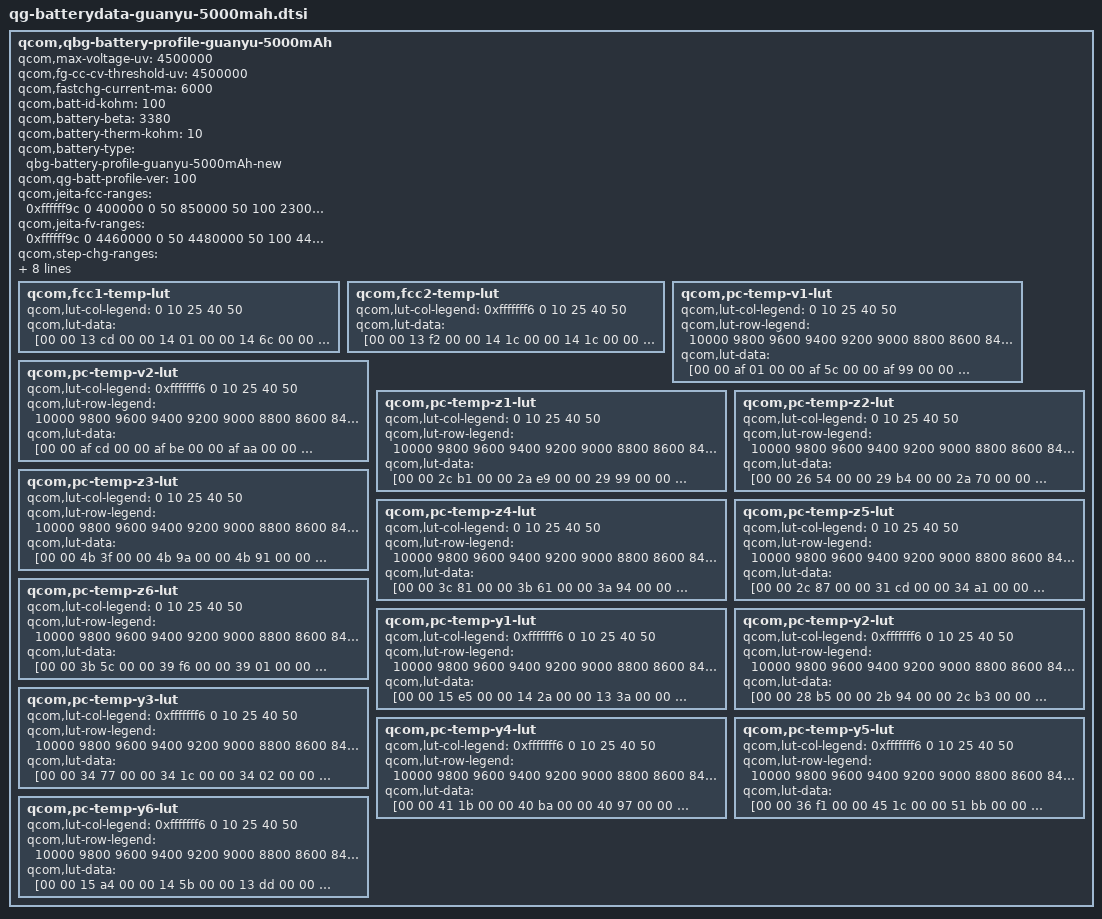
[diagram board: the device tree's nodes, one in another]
// SPDX-License-Identifier: GPL-2.0-only
/* QG battery profile qcom,qbg-battery-profile-guanyu-5000mAh (sapphire, reconstructed from stock dtbo) */

qcom,qbg-battery-profile-guanyu-5000mAh {
	qcom,max-voltage-uv = <4500000>;
	qcom,fg-cc-cv-threshold-uv = <4500000>;
	qcom,fastchg-current-ma = <6000>;
	qcom,batt-id-kohm = <100>;
	qcom,battery-beta = <3380>;
	qcom,battery-therm-kohm = <10>;
	qcom,battery-type = "qbg-battery-profile-guanyu-5000mAh-new";
	qcom,qg-batt-profile-ver = <100>;
	qcom,jeita-fcc-ranges = <0xffffff9c 0 400000 0 50 850000 50 100
	                         2300000 100 150 3700000 150 350 6000000 350
	                         480 6000000 480 560 2300000 560 1500 0>;
	qcom,jeita-fv-ranges = <0xffffff9c 0 4460000 0 50 4480000 50 100
	                        4480000 100 150 4480000 150 350 4450000 350
	                        480 4450000 480 560 4100000 560 1500 4100000>;
	qcom,step-chg-ranges = <3600000 4250000 6000000 4250001 4480000 5400000 4480001 4500000
	                        3920000>;
	qcom,vbat-avg-based-step-chg;
	qcom,taper-fcc;
	qcom,jeita-soft-thresholds = <9556 3725>;
	qcom,jeita-hard-thresholds = <17365 2971>;
	qcom,jeita-soft-hys-thresholds = <8799 4060>;
	qcom,jeita-soft-fcc-ua = <5400000 2500000>;
	qcom,jeita-soft-fv-uv = <4480000 4100000>;

	qcom,fcc1-temp-lut {
		qcom,lut-col-legend = <0 10 25 40 50>;
		qcom,lut-data = [00 00 13 cd 00 00 14 01 00 00 14 6c 00 00 14 91 00 00 14 9a];
	};

	qcom,fcc2-temp-lut {
		qcom,lut-col-legend = <0xfffffff6 0 10 25 40 50>;
		qcom,lut-data = [00 00 13 f2 00 00 14 1c 00 00 14 1c 00 00 14 80 00 00 14 7c 00 00 14 73];
	};

	qcom,pc-temp-v1-lut {
		qcom,lut-col-legend = <0 10 25 40 50>;
		qcom,lut-row-legend = <10000 9800 9600 9400 9200 9000 8800 8600
		                       8400 8200 8000 7800 7600 7400 7200 7000
		                       6800 6600 6400 6200 6000 5800 5600 5400
		                       5200 5000 4800 4600 4400 4200 4000 3800
		                       3600 3400 3200 3000 2800 2600 2400 2200
		                       2000 1800 1600 1400 1200 1000 900 800
		                       700 600 500 400 300 200 100 0>;
		qcom,lut-data = [00 00 af 01 00 00 af 5c 00 00 af 99 00 00 af b8 00 00 af c0 00 00 ad b1 00 00 ad ce 00 00 ad ed 00 00 ae 01 00 00 ae 12 00 00 ac b4 00 00 ac c2 00 00 ac c4 00 00 ac bb 00 00 ac c3 00 00 ab cb 00 00 ab ea 00 00 ab d5 00 00 ab c2 00 00 ab c3 00 00 aa e4 00 00 ab 0c 00 00 aa fb 00 00 aa e5 00 00 aa e4 00 00 aa 03 00 00 aa 28 00 00 aa 19 00 00 aa 05 00 00 aa 06 00 00 a9 15 00 00 a9 40 00 00 a9 30 00 00 a9 19 00 00 a9 1c 00 00 a8 19 00 00 a8 4b 00 00 a8 40 00 00 a8 28 00 00 a8 2c 00 00 a7 19 00 00 a7 4e 00 00 a7 44 00 00 a7 2e 00 00 a7 35 00 00 a6 1a 00 00 a6 50 00 00 a6 41 00 00 a6 2e 00 00 a6 38 00 00 a5 1a 00 00 a5 50 00 00 a5 3e 00 00 a5 2e 00 00 a5 3a 00 00 a4 1f 00 00 a4 51 00 00 a4 39 00 00 a4 2e 00 00 a4 38 00 00 a3 27 00 00 a3 56 00 00 a3 3b 00 00 a3 31 00 00 a3 38 00 00 a2 35 00 00 a2 5e 00 00 a2 43 00 00 a2 37 00 00 a2 41 00 00 a1 4c 00 00 a1 71 00 00 a1 52 00 00 a1 43 00 00 a1 51 00 00 a0 6a 00 00 a0 8c 00 00 a0 67 00 00 a0 58 00 00 a0 66 00 00 9f 90 00 00 9f ae 00 00 9f 83 00 00 9f 75 00 00 9f 7f 00 00 9e bd 00 00 9e d9 00 00 9e ab 00 00 9e 9c 00 00 9e a2 00 00 9d f4 00 00 9e 0d 00 00 9d df 00 00 9d cc 00 00 9d d0 00 00 9d 38 00 00 9d 4d 00 00 9d 1a 00 00 9d 03 00 00 9d 05 00 00 9c 82 00 00 9c 96 00 00 9c 68 00 00 9c 4c 00 00 9c 4b 00 00 9b ca 00 00 9b d8 00 00 9b b3 00 00 9b 9b 00 00 9b 9a 00 00 9b 15 00 00 9b 15 00 00 9a c4 00 00 9a bf 00 00 9a ca 00 00 9a 4b 00 00 9a 45 00 00 99 9f 00 00 99 a2 00 00 99 c4 00 00 99 3f 00 00 99 43 00 00 98 ba 00 00 98 b7 00 00 98 dd 00 00 98 3a 00 00 98 2d 00 00 98 10 00 00 98 1f 00 00 98 3c 00 00 97 9b 00 00 97 88 00 00 97 88 00 00 97 a3 00 00 97 b4 00 00 97 2a 00 00 97 2c 00 00 97 22 00 00 97 30 00 00 97 34 00 00 96 d1 00 00 96 dd 00 00 96 cd 00 00 96 ca 00 00 96 bf 00 00 96 8a 00 00 96 8b 00 00 96 7b 00 00 96 67 00 00 96 54 00 00 96 4d 00 00 96 3d 00 00 96 2b 00 00 96 07 00 00 95 f5 00 00 96 10 00 00 95 f0 00 00 95 df 00 00 95 af 00 00 95 9e 00 00 95 d7 00 00 95 a3 00 00 95 94 00 00 95 64 00 00 95 50 00 00 95 9f 00 00 95 60 00 00 95 4f 00 00 95 20 00 00 95 08 00 00 95 69 00 00 95 28 00 00 95 14 00 00 94 e0 00 00 94 c5 00 00 95 38 00 00 94 f7 00 00 94 e1 00 00 94 a4 00 00 94 8a 00 00 95 0f 00 00 94 ce 00 00 94 b2 00 00 94 69 00 00 94 48 00 00 94 ec 00 00 94 ab 00 00 94 89 00 00 94 35 00 00 93 fe 00 00 94 bd 00 00 94 7e 00 00 94 58 00 00 93 f8 00 00 93 ac 00 00 94 7c 00 00 94 38 00 00 94 05 00 00 93 a1 00 00 93 54 00 00 94 2a 00 00 93 e0 00 00 93 96 00 00 93 32 00 00 92 f3 00 00 93 bb 00 00 93 78 00 00 93 1f 00 00 92 b9 00 00 92 82 00 00 93 2d 00 00 92 f8 00 00 92 9a 00 00 92 32 00 00 91 f9 00 00 92 8c 00 00 92 58 00 00 91 f8 00 00 91 95 00 00 91 5a 00 00 91 df 00 00 91 a5 00 00 91 55 00 00 90 f9 00 00 90 be 00 00 91 38 00 00 91 02 00 00 90 e8 00 00 90 99 00 00 90 65 00 00 90 fe 00 00 90 c6 00 00 90 cc 00 00 90 83 00 00 90 4e 00 00 90 bf 00 00 90 a2 00 00 90 b6 00 00 90 73 00 00 90 3f 00 00 90 7f 00 00 90 73 00 00 90 a0 00 00 90 59 00 00 90 27 00 00 90 24 00 00 90 39 00 00 90 65 00 00 8f f6 00 00 8f b8 00 00 8e f4 00 00 8f a5 00 00 8f 6c 00 00 8e bd 00 00 8e 73 00 00 7f a0 00 00 8e 09 00 00 8d a3 00 00 8c da 00 00 8c 8c 00 00 7c 55 00 00 7e 1a 00 00 8b 33 00 00 8a 65 00 00 8a 12 00 00 79 f7 00 00 79 7d 00 00 87 ba 00 00 86 f9 00 00 86 9e 00 00 77 54 00 00 76 98 00 00 81 ea 00 00 81 67 00 00 81 0d 00 00 75 30 00 00 75 30 00 00 75 30 00 00 75 30 00 00 75 30];
	};

	qcom,pc-temp-v2-lut {
		qcom,lut-col-legend = <0xfffffff6 0 10 25 40 50>;
		qcom,lut-row-legend = <10000 9800 9600 9400 9200 9000 8800 8600
		                       8400 8200 8000 7800 7600 7400 7200 7000
		                       6800 6600 6400 6200 6000 5800 5600 5400
		                       5200 5000 4800 4600 4400 4200 4000 3800
		                       3600 3400 3200 3000 2800 2600 2400 2200
		                       2000 1800 1600 1400 1200 1000 900 800
		                       700 600 500 400 300 200 100 0>;
		qcom,lut-data = [00 00 af cd 00 00 af be 00 00 af aa 00 00 af 6e 00 00 af 5a 00 00 af 46 00 00 ad d1 00 00 ad ee 00 00 ad ee 00 00 ad da 00 00 ad b6 00 00 ad a2 00 00 ac 2e 00 00 ac 6f 00 00 ac 7f 00 00 ac 83 00 00 ac 51 00 00 ac 3b 00 00 aa ff 00 00 ab 59 00 00 ab 72 00 00 ab 78 00 00 ab 3c 00 00 ab 23 00 00 aa 20 00 00 aa 8e 00 00 aa a9 00 00 aa a3 00 00 aa 5d 00 00 aa 42 00 00 a9 49 00 00 a9 c4 00 00 a9 dd 00 00 a9 c6 00 00 a9 7b 00 00 a9 5f 00 00 a8 5f 00 00 a8 e0 00 00 a8 f9 00 00 a8 d8 00 00 a8 8d 00 00 a8 71 00 00 a7 73 00 00 a7 f4 00 00 a8 0d 00 00 a7 e5 00 00 a7 9b 00 00 a7 7f 00 00 a6 81 00 00 a7 02 00 00 a7 19 00 00 a6 ea 00 00 a6 a1 00 00 a6 85 00 00 a5 87 00 00 a6 08 00 00 a6 1b 00 00 a5 e9 00 00 a5 a1 00 00 a5 86 00 00 a4 8e 00 00 a5 0f 00 00 a5 1d 00 00 a4 e9 00 00 a4 a2 00 00 a4 87 00 00 a3 95 00 00 a4 16 00 00 a4 20 00 00 a3 e6 00 00 a3 a3 00 00 a3 89 00 00 a2 9f 00 00 a3 1e 00 00 a3 26 00 00 a2 e8 00 00 a2 a7 00 00 a2 8f 00 00 a1 ba 00 00 a2 2c 00 00 a2 31 00 00 a1 ee 00 00 a1 b0 00 00 a1 9c 00 00 a0 e2 00 00 a1 3e 00 00 a1 42 00 00 a0 f9 00 00 a0 bf 00 00 a0 ae 00 00 a0 05 00 00 a0 5a 00 00 a0 59 00 00 a0 0d 00 00 9f d7 00 00 9f c6 00 00 9f 20 00 00 9f 86 00 00 9f 74 00 00 9f 28 00 00 9e f5 00 00 9e e5 00 00 9e 31 00 00 9e b7 00 00 9e 98 00 00 9e 4d 00 00 9e 1d 00 00 9e 0d 00 00 9d 2e 00 00 9d e5 00 00 9d cc 00 00 9d 7d 00 00 9d 4f 00 00 9d 3e 00 00 9c 18 00 00 9d 10 00 00 9d 03 00 00 9c ad 00 00 9c 86 00 00 9c 77 00 00 9b 12 00 00 9c 26 00 00 9c 1d 00 00 9b de 00 00 9b c9 00 00 9b bf 00 00 9a 21 00 00 9b 0b 00 00 9b 15 00 00 9b 0c 00 00 9b 0b 00 00 9b 0b 00 00 99 3f 00 00 99 f2 00 00 9a 19 00 00 9a 1f 00 00 9a 27 00 00 9a 2e 00 00 98 65 00 00 99 14 00 00 99 2e 00 00 99 14 00 00 99 14 00 00 99 1b 00 00 97 96 00 00 98 52 00 00 98 59 00 00 98 36 00 00 98 35 00 00 98 37 00 00 96 e6 00 00 97 a8 00 00 97 ac 00 00 97 8f 00 00 97 94 00 00 97 97 00 00 96 50 00 00 97 12 00 00 97 1c 00 00 97 02 00 00 97 0d 00 00 97 10 00 00 95 d1 00 00 96 89 00 00 96 99 00 00 96 84 00 00 96 93 00 00 96 97 00 00 95 6d 00 00 96 0a 00 00 96 21 00 00 96 16 00 00 96 25 00 00 96 2a 00 00 95 19 00 00 95 96 00 00 95 b3 00 00 95 af 00 00 95 c0 00 00 95 c5 00 00 94 ce 00 00 95 2b 00 00 95 4e 00 00 95 4e 00 00 95 65 00 00 95 67 00 00 94 8a 00 00 94 c5 00 00 94 f0 00 00 94 f6 00 00 95 12 00 00 95 11 00 00 94 4b 00 00 94 6d 00 00 94 9a 00 00 94 a7 00 00 94 c9 00 00 94 c8 00 00 94 0d 00 00 94 2c 00 00 94 4a 00 00 94 5e 00 00 94 84 00 00 94 83 00 00 93 d1 00 00 93 f8 00 00 94 01 00 00 94 19 00 00 94 37 00 00 94 33 00 00 93 90 00 00 93 c6 00 00 93 c1 00 00 93 d8 00 00 93 e6 00 00 93 d7 00 00 93 4a 00 00 93 97 00 00 93 85 00 00 93 90 00 00 93 8c 00 00 93 73 00 00 92 ff 00 00 93 65 00 00 93 45 00 00 93 3d 00 00 93 21 00 00 92 fc 00 00 92 ac 00 00 93 26 00 00 92 ff 00 00 92 e5 00 00 92 b7 00 00 92 86 00 00 92 51 00 00 92 dc 00 00 92 af 00 00 92 8c 00 00 92 5e 00 00 92 29 00 00 91 ec 00 00 92 7c 00 00 92 49 00 00 92 2c 00 00 92 08 00 00 91 d2 00 00 91 7a 00 00 91 f8 00 00 91 d1 00 00 91 be 00 00 91 9f 00 00 91 65 00 00 91 00 00 00 91 66 00 00 91 42 00 00 91 3d 00 00 91 25 00 00 90 e9 00 00 90 81 00 00 90 c7 00 00 90 9d 00 00 90 a6 00 00 90 99 00 00 90 5f 00 00 90 15 00 00 90 33 00 00 90 12 00 00 90 18 00 00 90 10 00 00 8f df 00 00 8f ac 00 00 8f c1 00 00 8f c5 00 00 8f eb 00 00 8f f6 00 00 8f c2 00 00 8f 79 00 00 8f 8e 00 00 8f 9e 00 00 8f d1 00 00 8f e2 00 00 8f b0 00 00 8f 42 00 00 8f 5f 00 00 8f 6b 00 00 8f a7 00 00 8f c5 00 00 8f 96 00 00 8f 34 00 00 8f 2b 00 00 8f 26 00 00 8f 58 00 00 8f 8b 00 00 8f 58 00 00 8e da 00 00 8e ed 00 00 8e 68 00 00 8e 80 00 00 8e c2 00 00 8e 90 00 00 8e 38 00 00 8e 84 00 00 8c e0 00 00 8c b1 00 00 8d 10 00 00 8c d2 00 00 8d c1 00 00 8d aa 00 00 8a 8f 00 00 8a 1b 00 00 8a c1 00 00 8a 94 00 00 8a 4f 00 00 8d b4 00 00 87 81 00 00 86 4e 00 00 87 af 00 00 87 94 00 00 7a 6a 00 00 8b ff 00 00 84 a3 00 00 82 18 00 00 83 05 00 00 83 2b 00 00 76 38 00 00 77 c9 00 00 7e f6 00 00 80 25 00 00 7b f3 00 00 7b a8 00 00 72 44 00 00 72 8c 00 00 6d d8 00 00 71 8c 00 00 6b dd 00 00 6b 8b];
	};

	qcom,pc-temp-z1-lut {
		qcom,lut-col-legend = <0 10 25 40 50>;
		qcom,lut-row-legend = <10000 9800 9600 9400 9200 9000 8800 8600
		                       8400 8200 8000 7800 7600 7400 7200 7000
		                       6800 6600 6400 6200 6000 5800 5600 5400
		                       5200 5000 4800 4600 4400 4200 4000 3800
		                       3600 3400 3200 3000 2800 2600 2400 2200
		                       2000 1800 1600 1400 1200 1000 900 800
		                       700 600 500 400 300 200 100 0>;
		qcom,lut-data = [00 00 2c b1 00 00 2a e9 00 00 29 99 00 00 28 f4 00 00 28 a9 00 00 2c de 00 00 2b 24 00 00 29 d4 00 00 29 26 00 00 28 ef 00 00 2c df 00 00 2b 22 00 00 29 d7 00 00 29 28 00 00 28 f0 00 00 2c e0 00 00 2b 2c 00 00 29 d2 00 00 29 20 00 00 28 eb 00 00 2c e9 00 00 2b 33 00 00 29 d3 00 00 29 1e 00 00 28 eb 00 00 2c fc 00 00 2b 37 00 00 29 d3 00 00 29 1e 00 00 28 eb 00 00 2d 00 00 00 2b 3a 00 00 29 d0 00 00 29 1e 00 00 28 eb 00 00 2c ed 00 00 2b 38 00 00 29 cc 00 00 29 1e 00 00 28 ec 00 00 2c d9 00 00 2b 32 00 00 29 c7 00 00 29 1d 00 00 28 ec 00 00 2c d1 00 00 2b 2d 00 00 29 c3 00 00 29 1a 00 00 28 ed 00 00 2c cb 00 00 2b 26 00 00 29 c3 00 00 29 19 00 00 28 ed 00 00 2c c6 00 00 2b 21 00 00 29 c3 00 00 29 19 00 00 28 ed 00 00 2c c2 00 00 2b 1e 00 00 29 c4 00 00 29 1a 00 00 28 ee 00 00 2c c0 00 00 2b 1c 00 00 29 c4 00 00 29 1a 00 00 28 ee 00 00 2c ca 00 00 2b 1c 00 00 29 c4 00 00 29 1b 00 00 28 f1 00 00 2c dd 00 00 2b 1e 00 00 29 c6 00 00 29 1d 00 00 28 f3 00 00 2c de 00 00 2b 1f 00 00 29 cb 00 00 29 1f 00 00 28 f5 00 00 2c d2 00 00 2b 1d 00 00 29 d0 00 00 29 22 00 00 28 f7 00 00 2c cb 00 00 2b 1b 00 00 29 d6 00 00 29 24 00 00 28 f9 00 00 2c cc 00 00 2b 1d 00 00 29 d9 00 00 29 27 00 00 28 fc 00 00 2c d0 00 00 2b 26 00 00 29 d9 00 00 29 2a 00 00 28 ff 00 00 2c d4 00 00 2b 2d 00 00 29 d9 00 00 29 2d 00 00 29 03 00 00 2c d9 00 00 2b 33 00 00 29 d9 00 00 29 2f 00 00 29 04 00 00 2c db 00 00 2b 37 00 00 29 dc 00 00 29 30 00 00 29 04 00 00 2c d7 00 00 2b 37 00 00 29 df 00 00 29 31 00 00 29 05 00 00 2c d1 00 00 2b 36 00 00 29 e4 00 00 29 34 00 00 29 06 00 00 2c d5 00 00 2b 36 00 00 29 e8 00 00 29 39 00 00 29 09 00 00 2c e5 00 00 2b 3c 00 00 29 eb 00 00 29 3c 00 00 29 0c 00 00 2c ec 00 00 2b 40 00 00 29 ef 00 00 29 3f 00 00 29 10 00 00 2c e7 00 00 2b 40 00 00 29 f2 00 00 29 42 00 00 29 13 00 00 2c e1 00 00 2b 3e 00 00 29 f5 00 00 29 45 00 00 29 16 00 00 2c e2 00 00 2b 3f 00 00 29 f9 00 00 29 48 00 00 29 19 00 00 2c e7 00 00 2b 47 00 00 2a 01 00 00 29 4d 00 00 29 1b 00 00 2c e8 00 00 2b 4b 00 00 2a 07 00 00 29 52 00 00 29 1d 00 00 2c df 00 00 2b 4a 00 00 2a 08 00 00 29 53 00 00 29 20 00 00 2c d6 00 00 2b 48 00 00 2a 07 00 00 29 53 00 00 29 23 00 00 2c df 00 00 2b 48 00 00 2a 07 00 00 29 53 00 00 29 26 00 00 2c f7 00 00 2b 49 00 00 2a 0b 00 00 29 58 00 00 29 27 00 00 2c ff 00 00 2b 4b 00 00 2a 11 00 00 29 5d 00 00 29 28 00 00 2c f7 00 00 2b 4b 00 00 2a 19 00 00 29 60 00 00 29 2a 00 00 2c f1 00 00 2b 4c 00 00 2a 23 00 00 29 62 00 00 29 2c 00 00 2c f9 00 00 2b 51 00 00 2a 26 00 00 29 65 00 00 29 2e 00 00 2d 05 00 00 2b 5b 00 00 2a 27 00 00 29 6a 00 00 29 30 00 00 2d 06 00 00 2b 6b 00 00 2a 2b 00 00 29 6c 00 00 29 33 00 00 2d 06 00 00 2b 70 00 00 2a 30 00 00 29 6d 00 00 29 35 00 00 2d 15 00 00 2b 65 00 00 2a 33 00 00 29 71 00 00 29 38 00 00 2d 28 00 00 2b 69 00 00 2a 37 00 00 29 72 00 00 29 39 00 00 2d 04 00 00 2b 59 00 00 2a 35 00 00 29 74 00 00 29 39 00 00 2d 04 00 00 2b 5e 00 00 2a 35 00 00 29 77 00 00 29 3a 00 00 2c fd 00 00 2b 5f 00 00 2a 3e 00 00 29 7a 00 00 29 3d 00 00 2c fc 00 00 2b 62 00 00 2a 3e 00 00 29 7d 00 00 29 41 00 00 2d 08 00 00 2b 5b 00 00 2a 49 00 00 29 81 00 00 29 47 00 00 2d 0e 00 00 2b 57 00 00 2a 57 00 00 29 8d 00 00 29 4e 00 00 2d 0e 00 00 2b 60 00 00 2a 69 00 00 29 9a 00 00 29 59 00 00 2d 0e 00 00 2b 60 00 00 2a 69 00 00 29 9a 00 00 29 59 00 00 2d 0e 00 00 2b 60 00 00 2a 69 00 00 29 9a 00 00 29 59];
	};

	qcom,pc-temp-z2-lut {
		qcom,lut-col-legend = <0 10 25 40 50>;
		qcom,lut-row-legend = <10000 9800 9600 9400 9200 9000 8800 8600
		                       8400 8200 8000 7800 7600 7400 7200 7000
		                       6800 6600 6400 6200 6000 5800 5600 5400
		                       5200 5000 4800 4600 4400 4200 4000 3800
		                       3600 3400 3200 3000 2800 2600 2400 2200
		                       2000 1800 1600 1400 1200 1000 900 800
		                       700 600 500 400 300 200 100 0>;
		qcom,lut-data = [00 00 26 54 00 00 29 b4 00 00 2a 70 00 00 2a 32 00 00 2a 31 00 00 29 32 00 00 2a 2e 00 00 2a a7 00 00 2b 73 00 00 2a 5a 00 00 29 45 00 00 2a 34 00 00 2a cf 00 00 2b e0 00 00 2a d6 00 00 29 56 00 00 29 f0 00 00 2a 81 00 00 2b 4a 00 00 2c 09 00 00 29 44 00 00 29 b4 00 00 2a 44 00 00 2b 09 00 00 2b c7 00 00 29 11 00 00 29 7f 00 00 2a 08 00 00 2a f5 00 00 2b 95 00 00 28 e6 00 00 29 53 00 00 29 c3 00 00 2a f4 00 00 2b a3 00 00 28 c1 00 00 29 2e 00 00 29 a1 00 00 2a f4 00 00 2b b8 00 00 28 a4 00 00 29 12 00 00 29 b0 00 00 2a f9 00 00 2b b3 00 00 28 93 00 00 29 12 00 00 29 ca 00 00 2b 0a 00 00 2b 96 00 00 28 86 00 00 29 33 00 00 29 db 00 00 2b 18 00 00 2b 8e 00 00 28 87 00 00 29 53 00 00 29 e7 00 00 2b 20 00 00 2b dd 00 00 28 a3 00 00 29 65 00 00 29 f8 00 00 2b 2b 00 00 2c 26 00 00 28 bf 00 00 29 74 00 00 2a 19 00 00 2b 52 00 00 2b da 00 00 28 cf 00 00 29 8a 00 00 2a 3b 00 00 2b 82 00 00 2b 44 00 00 28 dd 00 00 29 a5 00 00 2a 51 00 00 2b 6c 00 00 2b 2d 00 00 28 ec 00 00 29 c0 00 00 2a 64 00 00 2a f8 00 00 2b 64 00 00 28 fc 00 00 29 d9 00 00 2a 84 00 00 2a c7 00 00 2b b4 00 00 29 0e 00 00 29 f0 00 00 2a bc 00 00 2b 12 00 00 2c 59 00 00 29 28 00 00 2a 05 00 00 2a e8 00 00 2b 78 00 00 2c f2 00 00 29 3f 00 00 2a 19 00 00 2a f7 00 00 2b b8 00 00 2d 0a 00 00 29 41 00 00 2a 1e 00 00 2b 06 00 00 2b f2 00 00 2d 12 00 00 29 3d 00 00 2a 12 00 00 2b 3f 00 00 2c 58 00 00 2d 20 00 00 29 3b 00 00 2a 08 00 00 2b b8 00 00 2d 19 00 00 2d 38 00 00 29 3e 00 00 2a 0a 00 00 2b dd 00 00 2d 78 00 00 2d 5a 00 00 29 43 00 00 2a 10 00 00 2b 7b 00 00 2c f8 00 00 2d b7 00 00 29 42 00 00 2a 10 00 00 2b 0c 00 00 2c 5d 00 00 2e 19 00 00 29 3f 00 00 29 ff 00 00 2a d4 00 00 2c 6f 00 00 2e 16 00 00 29 3e 00 00 29 f2 00 00 2a ad 00 00 2c be 00 00 2d d7 00 00 29 46 00 00 2a 08 00 00 2a cd 00 00 2c cd 00 00 2d 76 00 00 29 50 00 00 2a 2c 00 00 2b 99 00 00 2c 63 00 00 2c 98 00 00 29 50 00 00 2a 35 00 00 2c 0a 00 00 2b ed 00 00 2b cd 00 00 29 4f 00 00 2a 36 00 00 2b 9e 00 00 2b 9d 00 00 2b 71 00 00 29 4f 00 00 2a 37 00 00 2b 1d 00 00 2b 62 00 00 2b 35 00 00 29 57 00 00 2a 2c 00 00 2b 12 00 00 2b 88 00 00 2b 4a 00 00 29 60 00 00 2a 1e 00 00 2b 12 00 00 2c 49 00 00 2b f1 00 00 29 60 00 00 2a 1e 00 00 2b 16 00 00 2c f6 00 00 2c d0 00 00 29 60 00 00 2a 26 00 00 2b 4b 00 00 2d 89 00 00 2e 50 00 00 29 60 00 00 2a 2f 00 00 2b 87 00 00 2d e1 00 00 2f 7d 00 00 29 63 00 00 2a 35 00 00 2b b1 00 00 2d d9 00 00 2f 71 00 00 29 67 00 00 2a 3d 00 00 2b d1 00 00 2d be 00 00 2f 23 00 00 29 6b 00 00 2a 47 00 00 2b c4 00 00 2d a0 00 00 2e 9c 00 00 29 70 00 00 2a 54 00 00 2b 84 00 00 2d 76 00 00 2d 92 00 00 29 9e 00 00 2a 62 00 00 2b 76 00 00 2c b2 00 00 2d 43 00 00 29 a3 00 00 2a c2 00 00 2b 7e 00 00 2b c0 00 00 2d 27 00 00 29 38 00 00 2b 67 00 00 2b c6 00 00 2c 0a 00 00 2c e1 00 00 26 a1 00 00 2b 4f 00 00 2b ac 00 00 2b fb 00 00 2d 08 00 00 26 57 00 00 2b 19 00 00 2b 71 00 00 2c 12 00 00 2d 05 00 00 26 07 00 00 2a e5 00 00 2b 48 00 00 2c 45 00 00 2d d6 00 00 27 49 00 00 2a 95 00 00 2b 39 00 00 2d 01 00 00 2d b0 00 00 2d 92 00 00 2a 3c 00 00 2b fd 00 00 2b a9 00 00 2b 5c 00 00 ff ff 00 00 29 d4 00 00 2b 90 00 00 2a 63 00 00 2a 5a 00 00 ff ff 00 00 ff ff 00 00 29 fb 00 00 29 f1 00 00 2a 61 00 00 25 eb 00 00 29 e0 00 00 29 67 00 00 29 74 00 00 2a 2f 00 00 25 eb 00 00 29 e0 00 00 29 67 00 00 29 74 00 00 2a 2f 00 00 25 eb 00 00 29 e0 00 00 29 67 00 00 29 74 00 00 2a 2f];
	};

	qcom,pc-temp-z3-lut {
		qcom,lut-col-legend = <0 10 25 40 50>;
		qcom,lut-row-legend = <10000 9800 9600 9400 9200 9000 8800 8600
		                       8400 8200 8000 7800 7600 7400 7200 7000
		                       6800 6600 6400 6200 6000 5800 5600 5400
		                       5200 5000 4800 4600 4400 4200 4000 3800
		                       3600 3400 3200 3000 2800 2600 2400 2200
		                       2000 1800 1600 1400 1200 1000 900 800
		                       700 600 500 400 300 200 100 0>;
		qcom,lut-data = [00 00 4b 3f 00 00 4b 9a 00 00 4b 91 00 00 4b 79 00 00 4b 76 00 00 4c 76 00 00 4c 40 00 00 4b d6 00 00 4b 9e 00 00 4b 7f 00 00 4c b9 00 00 4c 64 00 00 4b f8 00 00 4b 9a 00 00 4b 7f 00 00 4c de 00 00 4c 6c 00 00 4c 1a 00 00 4b ce 00 00 4b ab 00 00 4c eb 00 00 4c 73 00 00 4c 1f 00 00 4b d1 00 00 4b af 00 00 4c f3 00 00 4c 7a 00 00 4c 1f 00 00 4b d1 00 00 4b b0 00 00 4c fa 00 00 4c 7e 00 00 4c 1c 00 00 4b ce 00 00 4b af 00 00 4d 02 00 00 4c 7d 00 00 4c 17 00 00 4b c8 00 00 4b ac 00 00 4d 06 00 00 4c 7a 00 00 4c 0b 00 00 4b c2 00 00 4b a7 00 00 4d 03 00 00 4c 74 00 00 4b fd 00 00 4b bb 00 00 4b 9d 00 00 4c fa 00 00 4c 5e 00 00 4b f6 00 00 4b b4 00 00 4b 99 00 00 4c f0 00 00 4c 4c 00 00 4b f2 00 00 4b ad 00 00 4b 99 00 00 4c e2 00 00 4c 45 00 00 4b ed 00 00 4b a6 00 00 4b 98 00 00 4c d3 00 00 4c 40 00 00 4b e3 00 00 4b a2 00 00 4b 91 00 00 4c c7 00 00 4c 37 00 00 4b d8 00 00 4b 9e 00 00 4b 83 00 00 4c bc 00 00 4c 2c 00 00 4b d1 00 00 4b 97 00 00 4b 7e 00 00 4c b2 00 00 4c 23 00 00 4b cb 00 00 4b 89 00 00 4b 7c 00 00 4c ab 00 00 4c 1c 00 00 4b c4 00 00 4b 81 00 00 4b 7b 00 00 4c a3 00 00 4c 18 00 00 4b b9 00 00 4b 7e 00 00 4b 79 00 00 4c 99 00 00 4c 16 00 00 4b b3 00 00 4b 7c 00 00 4b 76 00 00 4c 91 00 00 4c 15 00 00 4b b0 00 00 4b 7a 00 00 4b 73 00 00 4c 91 00 00 4c 15 00 00 4b af 00 00 4b 79 00 00 4b 6f 00 00 4c 97 00 00 4c 1b 00 00 4b b6 00 00 4b 7b 00 00 4b 6f 00 00 4c 9f 00 00 4c 23 00 00 4b cc 00 00 4b 88 00 00 4b 71 00 00 4c b1 00 00 4c 2a 00 00 4b d3 00 00 4b 8f 00 00 4b 73 00 00 4c c3 00 00 4c 31 00 00 4b ca 00 00 4b 80 00 00 4b 69 00 00 4c c3 00 00 4c 31 00 00 4b bd 00 00 4b 6e 00 00 4b 5a 00 00 4c bc 00 00 4c 21 00 00 4b b2 00 00 4b 6d 00 00 4b 67 00 00 4c b4 00 00 4c 15 00 00 4b a8 00 00 4b 70 00 00 4b 96 00 00 4c ad 00 00 4c 15 00 00 4b a7 00 00 4b 76 00 00 4b a7 00 00 4c a6 00 00 4c 15 00 00 4b ae 00 00 4b 93 00 00 4b 9f 00 00 4c a1 00 00 4c 17 00 00 4b b7 00 00 4b a7 00 00 4b 93 00 00 4c 9e 00 00 4c 26 00 00 4b c9 00 00 4b a2 00 00 4b 8a 00 00 4c 9c 00 00 4c 2f 00 00 4b da 00 00 4b 98 00 00 4b 82 00 00 4c 9c 00 00 4c 2d 00 00 4b d8 00 00 4b 92 00 00 4b 7b 00 00 4c 9c 00 00 4c 29 00 00 4b cf 00 00 4b 8d 00 00 4b 74 00 00 4c 9a 00 00 4c 24 00 00 4b c6 00 00 4b 89 00 00 4b 72 00 00 4c 96 00 00 4c 1e 00 00 4b be 00 00 4b 87 00 00 4b 76 00 00 4c 91 00 00 4c 18 00 00 4b b9 00 00 4b 86 00 00 4b 7a 00 00 4c 8a 00 00 4c 15 00 00 4b b8 00 00 4b 87 00 00 4b 7a 00 00 4c 82 00 00 4c 12 00 00 4b b8 00 00 4b 8a 00 00 4b 79 00 00 4c 7a 00 00 4c 09 00 00 4b b7 00 00 4b 89 00 00 4b 76 00 00 4c 6f 00 00 4b fc 00 00 4b b5 00 00 4b 85 00 00 4b 6e 00 00 4c 5e 00 00 4b f6 00 00 4b b3 00 00 4b 7e 00 00 4b 71 00 00 4b ff 00 00 4b e8 00 00 4b af 00 00 4b 78 00 00 4b 78 00 00 4b 8d 00 00 4b cf 00 00 4b 9f 00 00 4b 76 00 00 4b 68 00 00 4b 49 00 00 4b ce 00 00 4b 9d 00 00 4b 73 00 00 4b 66 00 00 4b 4a 00 00 4b 87 00 00 4b 96 00 00 4b 6e 00 00 4b 62 00 00 4b 4d 00 00 4b 71 00 00 4b 83 00 00 4b 69 00 00 4b 57 00 00 4b 74 00 00 4b 71 00 00 4b 7b 00 00 4b 66 00 00 4b 57 00 00 4c 44 00 00 4b e4 00 00 4b 6c 00 00 4b 6d 00 00 4b 71 00 00 4b 41 00 00 4b f1 00 00 4b 69 00 00 4b 81 00 00 4b 7d 00 00 4b 3c 00 00 4b 3f 00 00 4b 7c 00 00 4b 86 00 00 4b 7f 00 00 52 d4 00 00 51 a7 00 00 4b c7 00 00 4b 88 00 00 4b 80 00 00 52 d4 00 00 51 a7 00 00 4b c7 00 00 4b 88 00 00 4b 80 00 00 52 d4 00 00 51 a7 00 00 4b c7 00 00 4b 88 00 00 4b 80];
	};

	qcom,pc-temp-z4-lut {
		qcom,lut-col-legend = <0 10 25 40 50>;
		qcom,lut-row-legend = <10000 9800 9600 9400 9200 9000 8800 8600
		                       8400 8200 8000 7800 7600 7400 7200 7000
		                       6800 6600 6400 6200 6000 5800 5600 5400
		                       5200 5000 4800 4600 4400 4200 4000 3800
		                       3600 3400 3200 3000 2800 2600 2400 2200
		                       2000 1800 1600 1400 1200 1000 900 800
		                       700 600 500 400 300 200 100 0>;
		qcom,lut-data = [00 00 3c 81 00 00 3b 61 00 00 3a 94 00 00 3a 18 00 00 39 f3 00 00 3e 9f 00 00 3b d3 00 00 3a 0e 00 00 39 9b 00 00 39 8b 00 00 3d a4 00 00 3c 05 00 00 3a 41 00 00 39 85 00 00 39 73 00 00 3c 72 00 00 3b 42 00 00 3a 76 00 00 39 e0 00 00 39 ae 00 00 3b cc 00 00 3a c2 00 00 3a 37 00 00 39 c8 00 00 39 9d 00 00 3b 4d 00 00 3a 79 00 00 3a 0b 00 00 39 af 00 00 39 8b 00 00 3a ee 00 00 3a 43 00 00 39 ee 00 00 39 9d 00 00 39 7f 00 00 3a a4 00 00 3a 18 00 00 39 d8 00 00 39 90 00 00 39 75 00 00 3a 6b 00 00 39 f7 00 00 39 c8 00 00 39 8a 00 00 39 73 00 00 3a 40 00 00 39 e0 00 00 39 bb 00 00 39 87 00 00 39 73 00 00 3a 1e 00 00 39 ce 00 00 39 ae 00 00 39 83 00 00 39 71 00 00 39 fe 00 00 39 c1 00 00 39 a3 00 00 39 7f 00 00 39 67 00 00 39 dc 00 00 39 b5 00 00 39 99 00 00 39 7b 00 00 39 5e 00 00 39 c7 00 00 39 ab 00 00 39 93 00 00 39 73 00 00 39 5f 00 00 39 bf 00 00 39 a4 00 00 39 8c 00 00 39 6b 00 00 39 62 00 00 39 ba 00 00 39 9f 00 00 39 83 00 00 39 69 00 00 39 61 00 00 39 b5 00 00 39 9a 00 00 39 79 00 00 39 69 00 00 39 58 00 00 39 b0 00 00 39 92 00 00 39 72 00 00 39 68 00 00 39 4f 00 00 39 ab 00 00 39 8a 00 00 39 6d 00 00 39 60 00 00 39 46 00 00 39 a7 00 00 39 81 00 00 39 68 00 00 39 55 00 00 39 3f 00 00 39 a3 00 00 39 78 00 00 39 60 00 00 39 4e 00 00 39 3c 00 00 39 9e 00 00 39 75 00 00 39 58 00 00 39 48 00 00 39 39 00 00 39 97 00 00 39 78 00 00 39 66 00 00 39 4f 00 00 39 3f 00 00 39 94 00 00 39 7f 00 00 39 9a 00 00 39 83 00 00 39 70 00 00 39 bd 00 00 39 a5 00 00 39 c3 00 00 39 b1 00 00 39 9e 00 00 39 f3 00 00 39 eb 00 00 39 e2 00 00 39 ca 00 00 39 b5 00 00 39 fd 00 00 39 fe 00 00 39 f3 00 00 39 d9 00 00 39 c3 00 00 3a 00 00 00 39 fa 00 00 39 f2 00 00 39 d6 00 00 39 b1 00 00 3a 00 00 00 39 f3 00 00 39 ee 00 00 39 c9 00 00 39 72 00 00 39 f6 00 00 39 e7 00 00 39 e6 00 00 39 b4 00 00 39 55 00 00 39 e7 00 00 39 d5 00 00 39 d1 00 00 39 85 00 00 39 51 00 00 39 d9 00 00 39 c0 00 00 39 b8 00 00 39 62 00 00 39 4f 00 00 39 cc 00 00 39 a5 00 00 39 95 00 00 39 59 00 00 39 4b 00 00 39 c0 00 00 39 93 00 00 39 78 00 00 39 54 00 00 39 47 00 00 39 b5 00 00 39 8c 00 00 39 70 00 00 39 51 00 00 39 46 00 00 39 ac 00 00 39 87 00 00 39 6c 00 00 39 4f 00 00 39 45 00 00 39 a5 00 00 39 83 00 00 39 6b 00 00 39 4f 00 00 39 46 00 00 39 9f 00 00 39 7e 00 00 39 6a 00 00 39 51 00 00 39 4c 00 00 39 99 00 00 39 7c 00 00 39 6a 00 00 39 54 00 00 39 53 00 00 39 93 00 00 39 7d 00 00 39 74 00 00 39 5b 00 00 39 53 00 00 39 8d 00 00 39 7e 00 00 39 85 00 00 39 62 00 00 39 53 00 00 39 86 00 00 39 7c 00 00 39 85 00 00 39 63 00 00 39 53 00 00 39 80 00 00 39 75 00 00 39 7a 00 00 39 60 00 00 39 53 00 00 39 7b 00 00 39 6e 00 00 39 77 00 00 39 63 00 00 39 51 00 00 39 a5 00 00 39 60 00 00 39 73 00 00 39 69 00 00 39 49 00 00 39 f5 00 00 39 55 00 00 39 5c 00 00 39 4e 00 00 39 44 00 00 3a 3a 00 00 39 56 00 00 39 55 00 00 39 45 00 00 39 39 00 00 3a 3b 00 00 39 9c 00 00 39 48 00 00 39 35 00 00 39 2b 00 00 3a 39 00 00 39 ad 00 00 39 4a 00 00 39 2a 00 00 39 26 00 00 3a 19 00 00 39 ac 00 00 39 55 00 00 39 3a 00 00 39 32 00 00 39 9e 00 00 39 4d 00 00 39 85 00 00 39 44 00 00 39 24 00 00 43 12 00 00 39 98 00 00 39 99 00 00 39 33 00 00 39 1b 00 00 43 be 00 00 42 31 00 00 39 8c 00 00 39 30 00 00 39 1c 00 00 3a 45 00 00 3a 7f 00 00 39 46 00 00 39 35 00 00 39 22 00 00 3a 45 00 00 3a 7f 00 00 39 46 00 00 39 35 00 00 39 22 00 00 3a 45 00 00 3a 7f 00 00 39 46 00 00 39 35 00 00 39 22];
	};

	qcom,pc-temp-z5-lut {
		qcom,lut-col-legend = <0 10 25 40 50>;
		qcom,lut-row-legend = <10000 9800 9600 9400 9200 9000 8800 8600
		                       8400 8200 8000 7800 7600 7400 7200 7000
		                       6800 6600 6400 6200 6000 5800 5600 5400
		                       5200 5000 4800 4600 4400 4200 4000 3800
		                       3600 3400 3200 3000 2800 2600 2400 2200
		                       2000 1800 1600 1400 1200 1000 900 800
		                       700 600 500 400 300 200 100 0>;
		qcom,lut-data = [00 00 2c 87 00 00 31 cd 00 00 34 a1 00 00 37 a5 00 00 3a 57 00 00 37 a5 00 00 41 24 00 00 48 67 00 00 49 42 00 00 41 cb 00 00 3c 1c 00 00 41 fd 00 00 4d 49 00 00 54 b4 00 00 4a f2 00 00 3f fd 00 00 45 0b 00 00 4a c2 00 00 50 36 00 00 52 94 00 00 42 bb 00 00 48 17 00 00 4d 35 00 00 51 bf 00 00 55 4c 00 00 44 f4 00 00 4b 53 00 00 4d df 00 00 53 9a 00 00 57 47 00 00 47 b2 00 00 4e 2b 00 00 4d b0 00 00 55 c7 00 00 5a 1f 00 00 4b 66 00 00 50 53 00 00 4d 8e 00 00 57 84 00 00 5c 70 00 00 4e c2 00 00 52 00 00 00 4d 99 00 00 56 e4 00 00 5b 30 00 00 50 c1 00 00 52 79 00 00 4d b7 00 00 54 5e 00 00 55 6e 00 00 52 66 00 00 52 92 00 00 4e ac 00 00 52 2f 00 00 53 32 00 00 55 7f 00 00 52 bb 00 00 51 b5 00 00 50 2c 00 00 57 a5 00 00 5c 14 00 00 54 f8 00 00 52 fa 00 00 4f 1b 00 00 5b c5 00 00 60 72 00 00 57 f9 00 00 52 6f 00 00 50 1d 00 00 57 0c 00 00 60 c9 00 00 58 3f 00 00 51 eb 00 00 51 bd 00 00 4d b1 00 00 60 f9 00 00 57 a4 00 00 53 70 00 00 50 9e 00 00 4c 38 00 00 61 ab 00 00 57 61 00 00 56 b0 00 00 4b 39 00 00 4f 18 00 00 63 ae 00 00 59 7c 00 00 57 93 00 00 48 e6 00 00 52 d8 00 00 65 1f 00 00 5d 61 00 00 57 a3 00 00 4b 1b 00 00 57 b0 00 00 65 66 00 00 61 cb 00 00 57 c2 00 00 4e e2 00 00 5c e8 00 00 65 9c 00 00 67 d0 00 00 5b 7b 00 00 53 19 00 00 61 60 00 00 68 68 00 00 70 35 00 00 64 78 00 00 59 13 00 00 65 55 00 00 75 c6 00 00 7f 29 00 00 82 0d 00 00 64 c1 00 00 66 7d 00 00 89 1d 00 00 8e 51 00 00 c3 68 00 00 7e c1 00 00 66 b5 00 00 b3 d9 00 00 99 15 00 00 d8 27 00 00 8c 01 00 00 66 c3 00 00 de 22 00 00 a1 b8 00 00 ac a3 00 00 70 bc 00 00 56 75 00 00 da 94 00 00 9f de 00 00 7c 3f 00 00 4d 28 00 00 3f b7 00 00 ba f9 00 00 81 94 00 00 65 d6 00 00 44 18 00 00 44 83 00 00 a1 3c 00 00 67 fe 00 00 56 63 00 00 3f be 00 00 5c 7f 00 00 90 2e 00 00 62 83 00 00 52 6f 00 00 40 62 00 00 66 3e 00 00 85 75 00 00 5f 6b 00 00 51 38 00 00 50 7c 00 00 66 b6 00 00 84 c3 00 00 62 c0 00 00 51 1e 00 00 60 8b 00 00 67 30 00 00 84 f9 00 00 77 4c 00 00 64 b3 00 00 66 ad 00 00 68 d0 00 00 85 dc 00 00 8a 16 00 00 80 07 00 00 6b 82 00 00 6b 9b 00 00 8f 78 00 00 96 0d 00 00 8b f1 00 00 74 88 00 00 6e 96 00 00 98 c5 00 00 9e 1c 00 00 93 be 00 00 82 32 00 00 72 04 00 00 99 28 00 00 9e 2d 00 00 95 34 00 00 87 39 00 00 76 af 00 00 98 cf 00 00 9a ef 00 00 90 63 00 00 85 61 00 00 80 4f 00 00 97 e9 00 00 96 b8 00 00 88 df 00 00 81 c4 00 00 87 fd 00 00 92 ec 00 00 91 3a 00 00 7d 33 00 00 78 e3 00 00 80 49 00 00 8b da 00 00 89 8e 00 00 6f 54 00 00 6a 6f 00 00 6b d4 00 00 85 09 00 00 7a e3 00 00 68 92 00 00 61 71 00 00 5d c7 00 00 7c bd 00 00 69 cb 00 00 64 f0 00 00 5b f2 00 00 53 fd 00 00 72 85 00 00 67 30 00 00 5f 55 00 00 51 5b 00 00 54 4e 00 00 53 30 00 00 68 c0 00 00 5b e2 00 00 48 ec 00 00 57 a4 00 00 35 5b 00 00 69 26 00 00 5e 63 00 00 50 8b 00 00 4c b4 00 00 2e db 00 00 64 5b 00 00 5b 30 00 00 50 5c 00 00 50 7c 00 00 2e 51 00 00 3c 45 00 00 58 7d 00 00 54 46 00 00 53 2b 00 00 2e 18 00 00 34 bf 00 00 4b 88 00 00 5a ba 00 00 51 67 00 00 30 8e 00 00 34 2b 00 00 43 9b 00 00 4a fb 00 00 45 34 00 00 ab e7 00 00 a6 9f 00 00 37 a8 00 00 41 e4 00 00 65 bc 00 00 33 c2 00 00 60 fd 00 00 33 73 00 00 50 a0 00 00 88 bc 00 00 27 e1 00 00 29 2f 00 00 36 3b 00 00 56 69 00 00 8f 45 00 00 4a b4 00 00 33 51 00 00 61 af 00 00 55 77 00 00 85 4c 00 00 4a b4 00 00 33 51 00 00 61 af 00 00 55 77 00 00 85 4c 00 00 4a b4 00 00 33 51 00 00 61 af 00 00 55 77 00 00 85 4c];
	};

	qcom,pc-temp-z6-lut {
		qcom,lut-col-legend = <0 10 25 40 50>;
		qcom,lut-row-legend = <10000 9800 9600 9400 9200 9000 8800 8600
		                       8400 8200 8000 7800 7600 7400 7200 7000
		                       6800 6600 6400 6200 6000 5800 5600 5400
		                       5200 5000 4800 4600 4400 4200 4000 3800
		                       3600 3400 3200 3000 2800 2600 2400 2200
		                       2000 1800 1600 1400 1200 1000 900 800
		                       700 600 500 400 300 200 100 0>;
		qcom,lut-data = [00 00 3b 5c 00 00 39 f6 00 00 39 01 00 00 38 86 00 00 38 68 00 00 3c a8 00 00 3a 6e 00 00 38 f3 00 00 38 70 00 00 38 4b 00 00 3c 3c 00 00 3a 8c 00 00 39 13 00 00 38 64 00 00 38 41 00 00 3b b2 00 00 3a 31 00 00 39 38 00 00 38 a3 00 00 38 71 00 00 3b 5d 00 00 39 f3 00 00 39 1d 00 00 38 9a 00 00 38 6d 00 00 3b 17 00 00 39 cf 00 00 39 08 00 00 38 90 00 00 38 67 00 00 3a e1 00 00 39 b2 00 00 38 f9 00 00 38 87 00 00 38 61 00 00 3a b7 00 00 39 9a 00 00 38 ea 00 00 38 7e 00 00 38 5b 00 00 3a 94 00 00 39 85 00 00 38 dc 00 00 38 77 00 00 38 56 00 00 3a 74 00 00 39 70 00 00 38 ce 00 00 38 72 00 00 38 52 00 00 3a 59 00 00 39 5b 00 00 38 c5 00 00 38 6d 00 00 38 4e 00 00 3a 3e 00 00 39 4b 00 00 38 bd 00 00 38 67 00 00 38 4a 00 00 3a 22 00 00 39 41 00 00 38 b6 00 00 38 61 00 00 38 46 00 00 3a 0e 00 00 39 38 00 00 38 ad 00 00 38 5c 00 00 38 42 00 00 3a 02 00 00 39 30 00 00 38 a5 00 00 38 57 00 00 38 3d 00 00 39 fa 00 00 39 27 00 00 38 9d 00 00 38 51 00 00 38 38 00 00 39 f3 00 00 39 1f 00 00 38 96 00 00 38 4b 00 00 38 34 00 00 39 ec 00 00 39 18 00 00 38 8f 00 00 38 45 00 00 38 30 00 00 39 e6 00 00 39 13 00 00 38 88 00 00 38 40 00 00 38 2b 00 00 39 e0 00 00 39 0e 00 00 38 82 00 00 38 3b 00 00 38 27 00 00 39 db 00 00 39 0a 00 00 38 7e 00 00 38 38 00 00 38 24 00 00 39 db 00 00 39 09 00 00 38 7b 00 00 38 35 00 00 38 21 00 00 39 dc 00 00 39 0e 00 00 38 85 00 00 38 3a 00 00 38 23 00 00 39 df 00 00 39 17 00 00 38 a8 00 00 38 5a 00 00 38 3c 00 00 39 fd 00 00 39 2e 00 00 38 bc 00 00 38 6d 00 00 38 4e 00 00 3a 20 00 00 39 51 00 00 38 c4 00 00 38 6f 00 00 38 51 00 00 3a 24 00 00 39 59 00 00 38 c7 00 00 38 6f 00 00 38 53 00 00 3a 23 00 00 39 52 00 00 38 c5 00 00 38 6e 00 00 38 52 00 00 3a 21 00 00 39 49 00 00 38 be 00 00 38 6a 00 00 38 51 00 00 3a 1a 00 00 39 43 00 00 38 b9 00 00 38 66 00 00 38 4e 00 00 3a 11 00 00 39 3d 00 00 38 b5 00 00 38 62 00 00 38 49 00 00 3a 0a 00 00 39 39 00 00 38 b1 00 00 38 5e 00 00 38 43 00 00 3a 04 00 00 39 35 00 00 38 ae 00 00 38 58 00 00 38 3d 00 00 3a 00 00 00 39 32 00 00 38 aa 00 00 38 52 00 00 38 37 00 00 39 fd 00 00 39 30 00 00 38 a6 00 00 38 4d 00 00 38 33 00 00 39 fb 00 00 39 2e 00 00 38 a1 00 00 38 49 00 00 38 2f 00 00 39 f9 00 00 39 2b 00 00 38 9d 00 00 38 47 00 00 38 2d 00 00 39 f7 00 00 39 26 00 00 38 9a 00 00 38 48 00 00 38 32 00 00 39 f6 00 00 39 25 00 00 38 98 00 00 38 49 00 00 38 37 00 00 39 f6 00 00 39 26 00 00 38 9d 00 00 38 4c 00 00 38 37 00 00 39 f6 00 00 39 28 00 00 38 a6 00 00 38 51 00 00 38 37 00 00 39 f5 00 00 39 26 00 00 38 a7 00 00 38 52 00 00 38 36 00 00 39 f4 00 00 39 21 00 00 38 a2 00 00 38 4e 00 00 38 32 00 00 39 f2 00 00 39 1f 00 00 38 a2 00 00 38 4e 00 00 38 33 00 00 39 e2 00 00 39 19 00 00 38 a1 00 00 38 4d 00 00 38 35 00 00 39 cf 00 00 39 0a 00 00 38 91 00 00 38 42 00 00 38 2a 00 00 39 cd 00 00 39 0b 00 00 38 8d 00 00 38 3d 00 00 38 25 00 00 39 ce 00 00 39 05 00 00 38 85 00 00 38 33 00 00 38 1c 00 00 39 d1 00 00 39 03 00 00 38 7d 00 00 38 2b 00 00 38 14 00 00 39 da 00 00 39 05 00 00 38 7e 00 00 38 31 00 00 38 1a 00 00 3a 0d 00 00 39 1a 00 00 38 8e 00 00 38 3c 00 00 38 24 00 00 3d 8b 00 00 39 43 00 00 38 9a 00 00 38 42 00 00 38 28 00 00 3d e7 00 00 3c a2 00 00 38 a4 00 00 38 45 00 00 38 2b 00 00 3d dc 00 00 3d 04 00 00 38 b7 00 00 38 4b 00 00 38 32 00 00 3d dc 00 00 3d 04 00 00 38 b7 00 00 38 4b 00 00 38 32 00 00 3d dc 00 00 3d 04 00 00 38 b7 00 00 38 4b 00 00 38 32];
	};

	qcom,pc-temp-y1-lut {
		qcom,lut-col-legend = <0xfffffff6 0 10 25 40 50>;
		qcom,lut-row-legend = <10000 9800 9600 9400 9200 9000 8800 8600
		                       8400 8200 8000 7800 7600 7400 7200 7000
		                       6800 6600 6400 6200 6000 5800 5600 5400
		                       5200 5000 4800 4600 4400 4200 4000 3800
		                       3600 3400 3200 3000 2800 2600 2400 2200
		                       2000 1800 1600 1400 1200 1000 900 800
		                       700 600 500 400 300 200 100 0>;
		qcom,lut-data = [00 00 15 e5 00 00 14 2a 00 00 13 3a 00 00 12 7c 00 00 12 0c 00 00 11 ec 00 00 15 c9 00 00 14 29 00 00 13 3d 00 00 12 7c 00 00 12 0d 00 00 11 eb 00 00 15 b5 00 00 14 29 00 00 13 41 00 00 12 7d 00 00 12 0d 00 00 11 eb 00 00 15 a8 00 00 14 29 00 00 13 44 00 00 12 7d 00 00 12 0d 00 00 11 eb 00 00 15 a1 00 00 14 29 00 00 13 46 00 00 12 7c 00 00 12 0d 00 00 11 ea 00 00 15 a0 00 00 14 2a 00 00 13 47 00 00 12 7c 00 00 12 0d 00 00 11 ea 00 00 15 a8 00 00 14 2b 00 00 13 46 00 00 12 7c 00 00 12 0b 00 00 11 eb 00 00 15 b2 00 00 14 2d 00 00 13 45 00 00 12 7b 00 00 12 09 00 00 11 eb 00 00 15 b6 00 00 14 2d 00 00 13 45 00 00 12 7b 00 00 12 08 00 00 11 eb 00 00 15 b7 00 00 14 2c 00 00 13 45 00 00 12 7b 00 00 12 07 00 00 11 ea 00 00 15 b8 00 00 14 2c 00 00 13 44 00 00 12 7a 00 00 12 07 00 00 11 ea 00 00 15 b8 00 00 14 2d 00 00 13 44 00 00 12 7a 00 00 12 07 00 00 11 ea 00 00 15 b8 00 00 14 2e 00 00 13 42 00 00 12 7a 00 00 12 07 00 00 11 ea 00 00 15 b8 00 00 14 2e 00 00 13 42 00 00 12 7a 00 00 12 07 00 00 11 eb 00 00 15 b9 00 00 14 2f 00 00 13 41 00 00 12 79 00 00 12 07 00 00 11 ec 00 00 15 b9 00 00 14 2f 00 00 13 40 00 00 12 79 00 00 12 08 00 00 11 ed 00 00 15 bb 00 00 14 2f 00 00 13 40 00 00 12 79 00 00 12 09 00 00 11 ef 00 00 15 be 00 00 14 2f 00 00 13 40 00 00 12 79 00 00 12 0a 00 00 11 ef 00 00 15 c1 00 00 14 30 00 00 13 40 00 00 12 77 00 00 12 0a 00 00 11 ee 00 00 15 c4 00 00 14 32 00 00 13 40 00 00 12 76 00 00 12 0a 00 00 11 ed 00 00 15 c6 00 00 14 35 00 00 13 40 00 00 12 78 00 00 12 0a 00 00 11 ed 00 00 15 c8 00 00 14 39 00 00 13 40 00 00 12 7c 00 00 12 0a 00 00 11 ef 00 00 15 c9 00 00 14 3e 00 00 13 41 00 00 12 7e 00 00 12 0b 00 00 11 f0 00 00 15 c6 00 00 14 43 00 00 13 43 00 00 12 7e 00 00 12 0d 00 00 11 f1 00 00 15 c1 00 00 14 47 00 00 13 44 00 00 12 7f 00 00 12 0e 00 00 11 f2 00 00 15 be 00 00 14 47 00 00 13 44 00 00 12 83 00 00 12 10 00 00 11 f2 00 00 15 bd 00 00 14 47 00 00 13 42 00 00 12 87 00 00 12 11 00 00 11 f2 00 00 15 bb 00 00 14 47 00 00 13 42 00 00 12 87 00 00 12 12 00 00 11 f3 00 00 15 b1 00 00 14 48 00 00 13 49 00 00 12 86 00 00 12 12 00 00 11 f5 00 00 15 a6 00 00 14 49 00 00 13 50 00 00 12 86 00 00 12 13 00 00 11 f7 00 00 15 a2 00 00 14 47 00 00 13 4c 00 00 12 86 00 00 12 15 00 00 11 f8 00 00 15 a0 00 00 14 41 00 00 13 43 00 00 12 87 00 00 12 18 00 00 11 f9 00 00 15 a0 00 00 14 3c 00 00 13 41 00 00 12 88 00 00 12 1a 00 00 11 fa 00 00 15 af 00 00 14 38 00 00 13 43 00 00 12 8a 00 00 12 1b 00 00 11 fc 00 00 15 bf 00 00 14 34 00 00 13 44 00 00 12 8d 00 00 12 1d 00 00 11 fd 00 00 15 c0 00 00 14 31 00 00 13 45 00 00 12 93 00 00 12 1d 00 00 11 ff 00 00 15 be 00 00 14 2f 00 00 13 45 00 00 12 96 00 00 12 1f 00 00 12 01 00 00 15 bb 00 00 14 2e 00 00 13 47 00 00 12 94 00 00 12 21 00 00 12 02 00 00 15 b6 00 00 14 2f 00 00 13 4f 00 00 12 92 00 00 12 23 00 00 12 03 00 00 15 b2 00 00 14 2f 00 00 13 54 00 00 12 91 00 00 12 24 00 00 12 03 00 00 15 b2 00 00 14 2c 00 00 13 54 00 00 12 90 00 00 12 25 00 00 12 02 00 00 15 b3 00 00 14 2b 00 00 13 54 00 00 12 97 00 00 12 26 00 00 12 03 00 00 15 a4 00 00 14 2e 00 00 13 49 00 00 12 9c 00 00 12 26 00 00 12 07 00 00 15 96 00 00 14 2b 00 00 13 4a 00 00 12 9e 00 00 12 29 00 00 12 08 00 00 15 af 00 00 14 32 00 00 13 55 00 00 12 9a 00 00 12 28 00 00 12 08 00 00 15 c3 00 00 14 33 00 00 13 61 00 00 12 9b 00 00 12 2c 00 00 12 0a 00 00 15 be 00 00 14 39 00 00 13 50 00 00 12 a4 00 00 12 2e 00 00 12 0b 00 00 15 c9 00 00 14 41 00 00 13 50 00 00 12 a2 00 00 12 2d 00 00 12 0a 00 00 15 e0 00 00 14 5f 00 00 13 5d 00 00 12 a4 00 00 12 2e 00 00 12 0c 00 00 16 31 00 00 14 67 00 00 13 60 00 00 12 ac 00 00 12 30 00 00 12 0c 00 00 16 84 00 00 14 86 00 00 13 6e 00 00 12 b4 00 00 12 32 00 00 12 0d 00 00 16 f6 00 00 14 c7 00 00 13 77 00 00 12 c1 00 00 12 38 00 00 12 13 00 00 17 d7 00 00 15 4c 00 00 13 95 00 00 12 c3 00 00 12 3f 00 00 12 1a 00 00 17 d8 00 00 15 e1 00 00 13 e0 00 00 12 e1 00 00 12 4e 00 00 12 25 00 00 17 d8 00 00 15 e1 00 00 13 e0 00 00 12 e1 00 00 12 4e 00 00 12 25 00 00 17 d8 00 00 15 e1 00 00 13 e0 00 00 12 e1 00 00 12 4e 00 00 12 25];
	};

	qcom,pc-temp-y2-lut {
		qcom,lut-col-legend = <0xfffffff6 0 10 25 40 50>;
		qcom,lut-row-legend = <10000 9800 9600 9400 9200 9000 8800 8600
		                       8400 8200 8000 7800 7600 7400 7200 7000
		                       6800 6600 6400 6200 6000 5800 5600 5400
		                       5200 5000 4800 4600 4400 4200 4000 3800
		                       3600 3400 3200 3000 2800 2600 2400 2200
		                       2000 1800 1600 1400 1200 1000 900 800
		                       700 600 500 400 300 200 100 0>;
		qcom,lut-data = [00 00 28 b5 00 00 2b 94 00 00 2c b3 00 00 2e bc 00 00 2f 5a 00 00 2e f0 00 00 28 f9 00 00 2b 96 00 00 2c ad 00 00 2e 66 00 00 2f 2c 00 00 2f 6a 00 00 29 4d 00 00 2b 94 00 00 2c a1 00 00 2e 13 00 00 2e f4 00 00 2f 9b 00 00 29 a2 00 00 2b 91 00 00 2c 8f 00 00 2d c6 00 00 2e b4 00 00 2f 97 00 00 29 e8 00 00 2b 8b 00 00 2c 79 00 00 2d 84 00 00 2e 6c 00 00 2f 6f 00 00 2a 0d 00 00 2b 84 00 00 2c 5f 00 00 2d 53 00 00 2e 1c 00 00 2f 30 00 00 2a 1c 00 00 2b 7a 00 00 2c 3c 00 00 2d 2d 00 00 2d aa 00 00 2e 99 00 00 2a 26 00 00 2b 70 00 00 2c 1b 00 00 2d 0f 00 00 2d 5d 00 00 2e 05 00 00 2a 32 00 00 2b 65 00 00 2c 0b 00 00 2c f7 00 00 2d 78 00 00 2d c3 00 00 2a 3e 00 00 2b 5a 00 00 2c 00 00 00 2c e4 00 00 2d b0 00 00 2d 97 00 00 2a 4e 00 00 2b 58 00 00 2b fd 00 00 2c de 00 00 2d b5 00 00 2d 92 00 00 2a 65 00 00 2b 69 00 00 2c 04 00 00 2c db 00 00 2d 8a 00 00 2d a6 00 00 2a 82 00 00 2b 80 00 00 2c 11 00 00 2c db 00 00 2d 71 00 00 2d bd 00 00 2a a8 00 00 2b 95 00 00 2c 2a 00 00 2d 0c 00 00 2d 82 00 00 2d d2 00 00 2a d4 00 00 2b ac 00 00 2c 55 00 00 2d 5f 00 00 2d a2 00 00 2d eb 00 00 2a f5 00 00 2b c7 00 00 2c 85 00 00 2d a3 00 00 2d c0 00 00 2e 1e 00 00 2b 0c 00 00 2b eb 00 00 2c bf 00 00 2d e6 00 00 2d e4 00 00 2e 75 00 00 2b 1e 00 00 2c 0a 00 00 2c ee 00 00 2e 2d 00 00 2e 15 00 00 2e b7 00 00 2b 2d 00 00 2c 23 00 00 2d 0d 00 00 2e 7b 00 00 2e 60 00 00 2e db 00 00 2b 38 00 00 2c 34 00 00 2d 22 00 00 2e c0 00 00 2e c0 00 00 2f 09 00 00 2b 3c 00 00 2c 38 00 00 2d 22 00 00 2e fc 00 00 2f 67 00 00 2f 98 00 00 2b 3e 00 00 2c 39 00 00 2d 16 00 00 2f 28 00 00 30 15 00 00 30 51 00 00 2b 3e 00 00 2c 3c 00 00 2d 10 00 00 2f 02 00 00 30 1c 00 00 30 6b 00 00 29 a5 00 00 2c 5d 00 00 2d 1b 00 00 2e 4f 00 00 2f c3 00 00 30 44 00 00 27 02 00 00 2c 81 00 00 2d 2d 00 00 2d ff 00 00 2f 76 00 00 30 1d 00 00 26 51 00 00 2c 85 00 00 2d 40 00 00 2e 3a 00 00 2f 3e 00 00 2f fc 00 00 26 29 00 00 2c 86 00 00 2d 57 00 00 2e 7b 00 00 2f 1b 00 00 2f e4 00 00 26 11 00 00 2c 87 00 00 2d 70 00 00 2e 87 00 00 2f 72 00 00 30 24 00 00 25 ff 00 00 2c 88 00 00 2d 93 00 00 2e 8c 00 00 30 43 00 00 30 f2 00 00 25 f2 00 00 2c 89 00 00 2d ab 00 00 2e a2 00 00 30 74 00 00 31 a2 00 00 25 ea 00 00 2c 8b 00 00 2d ae 00 00 2e fe 00 00 30 2a 00 00 32 46 00 00 25 e4 00 00 2c 8e 00 00 2d af 00 00 2f 47 00 00 2f f8 00 00 32 9d 00 00 25 df 00 00 2c 86 00 00 2d af 00 00 2f 63 00 00 30 b9 00 00 32 9b 00 00 25 da 00 00 2c 45 00 00 2d a8 00 00 2f 73 00 00 31 cb 00 00 32 93 00 00 25 d6 00 00 2b f5 00 00 2d 9d 00 00 2f 74 00 00 31 d9 00 00 32 6b 00 00 25 d2 00 00 2b b9 00 00 2d 89 00 00 2f 74 00 00 31 85 00 00 31 e9 00 00 25 ce 00 00 2b 6b 00 00 2d 68 00 00 2f 72 00 00 31 0e 00 00 31 9d 00 00 25 cb 00 00 2a 62 00 00 2d 3b 00 00 2f 5d 00 00 30 1b 00 00 31 8f 00 00 25 c8 00 00 27 c9 00 00 2c f7 00 00 2f 37 00 00 2f 67 00 00 31 81 00 00 25 c7 00 00 26 59 00 00 2c a4 00 00 2e c6 00 00 2f ac 00 00 31 0f 00 00 25 c5 00 00 26 12 00 00 2c 39 00 00 2e 5d 00 00 30 0a 00 00 30 52 00 00 25 c3 00 00 25 ee 00 00 2b bd 00 00 2e 68 00 00 2f db 00 00 30 16 00 00 25 c0 00 00 25 dc 00 00 2b 35 00 00 2e 7f 00 00 2f 20 00 00 2f 89 00 00 25 bf 00 00 25 cf 00 00 28 44 00 00 2e 3b 00 00 2f e2 00 00 2f 55 00 00 25 c3 00 00 25 c7 00 00 27 b8 00 00 2d 74 00 00 2e c7 00 00 2f ca 00 00 26 24 00 00 25 be 00 00 26 62 00 00 2d 07 00 00 2e 70 00 00 2e 6f 00 00 25 c7 00 00 25 c6 00 00 25 fc 00 00 2c e8 00 00 2e 30 00 00 2d ec 00 00 25 bf 00 00 26 38 00 00 25 d2 00 00 2c a6 00 00 2d e8 00 00 2d d3 00 00 25 b9 00 00 25 db 00 00 25 c0 00 00 2c 3c 00 00 2d 82 00 00 2d 4c 00 00 25 ba 00 00 25 c2 00 00 25 e1 00 00 2b 7d 00 00 2d 60 00 00 2d 8d 00 00 25 b4 00 00 25 b8 00 00 25 e4 00 00 2a 4c 00 00 2c e3 00 00 2d 04 00 00 25 b3 00 00 25 b4 00 00 25 cc 00 00 28 be 00 00 2c 8f 00 00 2c de 00 00 25 b3 00 00 25 b4 00 00 25 b9 00 00 27 2f 00 00 2c 5b 00 00 2c fc 00 00 25 b3 00 00 25 b4 00 00 25 b7 00 00 26 6b 00 00 2b d0 00 00 2c 94 00 00 25 b3 00 00 25 b4 00 00 25 b7 00 00 26 6b 00 00 2b d0 00 00 2c 94 00 00 25 b3 00 00 25 b4 00 00 25 b7 00 00 26 6b 00 00 2b d0 00 00 2c 94];
	};

	qcom,pc-temp-y3-lut {
		qcom,lut-col-legend = <0xfffffff6 0 10 25 40 50>;
		qcom,lut-row-legend = <10000 9800 9600 9400 9200 9000 8800 8600
		                       8400 8200 8000 7800 7600 7400 7200 7000
		                       6800 6600 6400 6200 6000 5800 5600 5400
		                       5200 5000 4800 4600 4400 4200 4000 3800
		                       3600 3400 3200 3000 2800 2600 2400 2200
		                       2000 1800 1600 1400 1200 1000 900 800
		                       700 600 500 400 300 200 100 0>;
		qcom,lut-data = [00 00 34 77 00 00 34 1c 00 00 34 02 00 00 33 df 00 00 33 df 00 00 33 de 00 00 34 78 00 00 34 21 00 00 34 03 00 00 33 e3 00 00 33 db 00 00 33 d9 00 00 34 7c 00 00 34 25 00 00 34 05 00 00 33 e6 00 00 33 d9 00 00 33 d7 00 00 34 80 00 00 34 2a 00 00 34 06 00 00 33 e8 00 00 33 d8 00 00 33 d5 00 00 34 83 00 00 34 2d 00 00 34 07 00 00 33 e9 00 00 33 d7 00 00 33 d4 00 00 34 84 00 00 34 30 00 00 34 09 00 00 33 e9 00 00 33 d7 00 00 33 d4 00 00 34 84 00 00 34 32 00 00 34 0a 00 00 33 e8 00 00 33 d8 00 00 33 d6 00 00 34 84 00 00 34 33 00 00 34 0b 00 00 33 e7 00 00 33 d9 00 00 33 d7 00 00 34 83 00 00 34 33 00 00 34 0b 00 00 33 e8 00 00 33 dc 00 00 33 d8 00 00 34 82 00 00 34 33 00 00 34 0a 00 00 33 eb 00 00 33 e0 00 00 33 d9 00 00 34 80 00 00 34 32 00 00 34 0a 00 00 33 ed 00 00 33 e1 00 00 33 d9 00 00 34 7d 00 00 34 32 00 00 34 0a 00 00 33 ee 00 00 33 e2 00 00 33 da 00 00 34 7c 00 00 34 31 00 00 34 0a 00 00 33 ee 00 00 33 e3 00 00 33 da 00 00 34 7b 00 00 34 2f 00 00 34 0b 00 00 33 ee 00 00 33 e3 00 00 33 dd 00 00 34 7a 00 00 34 2e 00 00 34 0b 00 00 33 ee 00 00 33 e3 00 00 33 e0 00 00 34 79 00 00 34 2e 00 00 34 0b 00 00 33 ef 00 00 33 e4 00 00 33 e0 00 00 34 74 00 00 34 2f 00 00 34 08 00 00 33 f0 00 00 33 e7 00 00 33 e0 00 00 34 6c 00 00 34 30 00 00 34 06 00 00 33 f0 00 00 33 e8 00 00 33 e0 00 00 34 65 00 00 34 2e 00 00 34 07 00 00 33 ef 00 00 33 e7 00 00 33 df 00 00 34 5e 00 00 34 2b 00 00 34 09 00 00 33 ee 00 00 33 e7 00 00 33 de 00 00 34 58 00 00 34 27 00 00 34 08 00 00 33 ef 00 00 33 e7 00 00 33 e0 00 00 34 52 00 00 34 23 00 00 34 06 00 00 33 f0 00 00 33 e7 00 00 33 e4 00 00 34 4c 00 00 34 1f 00 00 34 03 00 00 33 ef 00 00 33 e6 00 00 33 e3 00 00 34 3f 00 00 34 1a 00 00 33 fe 00 00 33 ea 00 00 33 dd 00 00 33 da 00 00 34 32 00 00 34 16 00 00 33 fb 00 00 33 e6 00 00 33 d9 00 00 33 d5 00 00 34 30 00 00 34 14 00 00 33 fb 00 00 33 e3 00 00 33 d9 00 00 33 d5 00 00 34 32 00 00 34 12 00 00 33 fb 00 00 33 e1 00 00 33 d9 00 00 33 d5 00 00 34 35 00 00 34 11 00 00 33 fa 00 00 33 e2 00 00 33 d8 00 00 33 d5 00 00 34 38 00 00 34 10 00 00 33 f9 00 00 33 e4 00 00 33 d8 00 00 33 d7 00 00 34 3d 00 00 34 0e 00 00 33 f8 00 00 33 e5 00 00 33 d8 00 00 33 d7 00 00 34 45 00 00 34 09 00 00 33 f9 00 00 33 e6 00 00 33 d9 00 00 33 d6 00 00 34 53 00 00 34 01 00 00 33 f9 00 00 33 e6 00 00 33 d9 00 00 33 d5 00 00 34 63 00 00 34 00 00 00 33 f9 00 00 33 e6 00 00 33 da 00 00 33 d6 00 00 34 75 00 00 34 05 00 00 33 f9 00 00 33 e7 00 00 33 db 00 00 33 d8 00 00 34 8a 00 00 34 0b 00 00 33 f9 00 00 33 e7 00 00 33 db 00 00 33 d8 00 00 34 a5 00 00 34 11 00 00 33 f9 00 00 33 e6 00 00 33 db 00 00 33 d7 00 00 34 c6 00 00 34 16 00 00 33 fa 00 00 33 e6 00 00 33 da 00 00 33 d6 00 00 34 ee 00 00 34 1a 00 00 33 fb 00 00 33 e5 00 00 33 d8 00 00 33 d6 00 00 35 22 00 00 34 1d 00 00 33 fc 00 00 33 e5 00 00 33 d7 00 00 33 d5 00 00 35 62 00 00 34 23 00 00 33 fe 00 00 33 e3 00 00 33 d7 00 00 33 d5 00 00 35 af 00 00 34 31 00 00 33 ff 00 00 33 e2 00 00 33 d8 00 00 33 d7 00 00 36 16 00 00 34 47 00 00 34 01 00 00 33 e4 00 00 33 d9 00 00 33 d5 00 00 36 a6 00 00 34 6f 00 00 34 02 00 00 33 e4 00 00 33 da 00 00 33 d5 00 00 37 9f 00 00 34 a2 00 00 33 fe 00 00 33 e1 00 00 33 da 00 00 33 d7 00 00 39 51 00 00 35 05 00 00 33 ff 00 00 33 e0 00 00 33 d6 00 00 33 d5 00 00 3b 7b 00 00 36 90 00 00 34 1e 00 00 33 ea 00 00 33 dd 00 00 33 d7 00 00 35 47 00 00 39 90 00 00 34 43 00 00 33 ef 00 00 33 de 00 00 33 da 00 00 35 ad 00 00 3b 38 00 00 34 99 00 00 33 f3 00 00 33 e1 00 00 33 df 00 00 37 75 00 00 35 68 00 00 35 c2 00 00 33 fa 00 00 33 e5 00 00 33 df 00 00 41 d2 00 00 36 b6 00 00 3a 0e 00 00 33 fe 00 00 33 e5 00 00 33 dd 00 00 77 14 00 00 46 30 00 00 34 97 00 00 34 03 00 00 33 e2 00 00 33 dc 00 00 e1 22 00 00 67 da 00 00 35 cd 00 00 34 22 00 00 33 e3 00 00 33 df 00 00 ff ff 00 00 a1 f5 00 00 3c d8 00 00 35 28 00 00 33 e7 00 00 33 e1 00 00 ff ff 00 00 f5 6b 00 00 4a 25 00 00 34 59 00 00 33 ee 00 00 33 e5 00 00 ff ff 00 00 f5 6b 00 00 4a 25 00 00 34 59 00 00 33 ee 00 00 33 e5 00 00 ff ff 00 00 f5 6b 00 00 4a 25 00 00 34 59 00 00 33 ee 00 00 33 e5];
	};

	qcom,pc-temp-y4-lut {
		qcom,lut-col-legend = <0xfffffff6 0 10 25 40 50>;
		qcom,lut-row-legend = <10000 9800 9600 9400 9200 9000 8800 8600
		                       8400 8200 8000 7800 7600 7400 7200 7000
		                       6800 6600 6400 6200 6000 5800 5600 5400
		                       5200 5000 4800 4600 4400 4200 4000 3800
		                       3600 3400 3200 3000 2800 2600 2400 2200
		                       2000 1800 1600 1400 1200 1000 900 800
		                       700 600 500 400 300 200 100 0>;
		qcom,lut-data = [00 00 41 1b 00 00 40 ba 00 00 40 97 00 00 40 80 00 00 40 52 00 00 40 47 00 00 41 37 00 00 40 c7 00 00 40 9e 00 00 40 70 00 00 40 4e 00 00 40 44 00 00 41 62 00 00 40 dc 00 00 40 a4 00 00 40 65 00 00 40 4a 00 00 40 41 00 00 41 90 00 00 40 f4 00 00 40 a9 00 00 40 5d 00 00 40 46 00 00 40 3e 00 00 41 b5 00 00 41 06 00 00 40 ac 00 00 40 59 00 00 40 43 00 00 40 3c 00 00 41 c6 00 00 41 0c 00 00 40 ad 00 00 40 58 00 00 40 43 00 00 40 3a 00 00 41 cb 00 00 41 0b 00 00 40 ab 00 00 40 5d 00 00 40 44 00 00 40 39 00 00 41 cd 00 00 41 09 00 00 40 a8 00 00 40 62 00 00 40 45 00 00 40 38 00 00 41 cf 00 00 41 06 00 00 40 a8 00 00 40 65 00 00 40 44 00 00 40 39 00 00 41 d0 00 00 41 04 00 00 40 a9 00 00 40 66 00 00 40 41 00 00 40 3c 00 00 41 d1 00 00 41 03 00 00 40 a9 00 00 40 69 00 00 40 41 00 00 40 3e 00 00 41 d9 00 00 41 0a 00 00 40 ad 00 00 40 6f 00 00 40 45 00 00 40 42 00 00 41 e5 00 00 41 15 00 00 40 b3 00 00 40 77 00 00 40 4b 00 00 40 44 00 00 41 f0 00 00 41 24 00 00 40 bb 00 00 40 80 00 00 40 52 00 00 40 44 00 00 41 fb 00 00 41 39 00 00 40 c6 00 00 40 8a 00 00 40 59 00 00 40 45 00 00 41 fd 00 00 41 4f 00 00 40 d5 00 00 40 94 00 00 40 5d 00 00 40 47 00 00 41 ea 00 00 41 67 00 00 40 eb 00 00 40 9f 00 00 40 60 00 00 40 4d 00 00 41 cd 00 00 41 74 00 00 41 03 00 00 40 ae 00 00 40 65 00 00 40 55 00 00 41 ab 00 00 41 6a 00 00 41 1f 00 00 40 c8 00 00 40 70 00 00 40 5f 00 00 41 81 00 00 41 54 00 00 41 37 00 00 40 d9 00 00 40 7e 00 00 40 6a 00 00 41 5d 00 00 41 34 00 00 41 31 00 00 40 db 00 00 40 91 00 00 40 75 00 00 41 3a 00 00 41 01 00 00 41 07 00 00 40 db 00 00 40 a4 00 00 40 7f 00 00 41 28 00 00 40 d9 00 00 40 da 00 00 40 cb 00 00 40 9c 00 00 40 7a 00 00 41 30 00 00 40 bf 00 00 40 a9 00 00 40 86 00 00 40 6d 00 00 40 5b 00 00 41 3e 00 00 40 ad 00 00 40 83 00 00 40 62 00 00 40 51 00 00 40 47 00 00 41 3c 00 00 40 a8 00 00 40 7a 00 00 40 5d 00 00 40 4a 00 00 40 42 00 00 41 29 00 00 40 a5 00 00 40 75 00 00 40 5b 00 00 40 47 00 00 40 3f 00 00 41 1f 00 00 40 a2 00 00 40 74 00 00 40 5d 00 00 40 49 00 00 40 40 00 00 41 1f 00 00 40 9d 00 00 40 77 00 00 40 63 00 00 40 4f 00 00 40 43 00 00 41 20 00 00 40 9a 00 00 40 7a 00 00 40 6a 00 00 40 56 00 00 40 47 00 00 41 20 00 00 40 9b 00 00 40 7f 00 00 40 71 00 00 40 60 00 00 40 50 00 00 41 20 00 00 40 9c 00 00 40 83 00 00 40 78 00 00 40 69 00 00 40 5a 00 00 41 20 00 00 40 9e 00 00 40 85 00 00 40 81 00 00 40 73 00 00 40 62 00 00 41 24 00 00 40 9f 00 00 40 87 00 00 40 8a 00 00 40 7a 00 00 40 69 00 00 41 2b 00 00 40 a1 00 00 40 88 00 00 40 8f 00 00 40 79 00 00 40 68 00 00 41 31 00 00 40 aa 00 00 40 8c 00 00 40 92 00 00 40 73 00 00 40 62 00 00 41 38 00 00 40 b9 00 00 40 93 00 00 40 92 00 00 40 6a 00 00 40 5a 00 00 41 3e 00 00 40 cf 00 00 40 9b 00 00 40 83 00 00 40 59 00 00 40 4d 00 00 41 47 00 00 40 ef 00 00 40 a6 00 00 40 73 00 00 40 4d 00 00 40 42 00 00 41 4d 00 00 40 fc 00 00 40 ab 00 00 40 6f 00 00 40 4d 00 00 40 40 00 00 41 4b 00 00 40 fd 00 00 40 a9 00 00 40 6d 00 00 40 4d 00 00 40 3f 00 00 41 49 00 00 40 fd 00 00 40 a5 00 00 40 6d 00 00 40 4c 00 00 40 40 00 00 41 4b 00 00 40 fa 00 00 40 9d 00 00 40 6c 00 00 40 4c 00 00 40 41 00 00 41 4b 00 00 40 f7 00 00 40 b0 00 00 40 62 00 00 40 46 00 00 40 3d 00 00 41 40 00 00 40 e3 00 00 40 a3 00 00 40 56 00 00 40 3b 00 00 40 31 00 00 40 16 00 00 40 f1 00 00 40 ac 00 00 40 62 00 00 40 45 00 00 40 40 00 00 52 92 00 00 40 ed 00 00 40 bf 00 00 40 6f 00 00 40 4e 00 00 40 44 00 00 55 46 00 00 40 2f 00 00 40 dd 00 00 40 80 00 00 40 53 00 00 40 43 00 00 63 b3 00 00 55 c9 00 00 41 0a 00 00 40 9a 00 00 40 60 00 00 40 5b 00 00 45 29 00 00 43 ef 00 00 41 25 00 00 40 97 00 00 40 53 00 00 40 57 00 00 52 1a 00 00 45 a7 00 00 51 24 00 00 40 9a 00 00 40 45 00 00 40 3e 00 00 5e 22 00 00 50 1c 00 00 42 ac 00 00 40 d8 00 00 40 48 00 00 40 41 00 00 41 07 00 00 67 dc 00 00 44 56 00 00 41 fc 00 00 40 55 00 00 40 4c 00 00 42 02 00 00 aa 02 00 00 4c 8e 00 00 4c 76 00 00 40 7a 00 00 40 75 00 00 42 02 00 00 aa 02 00 00 4c 8e 00 00 4c 76 00 00 40 7a 00 00 40 75 00 00 42 02 00 00 aa 02 00 00 4c 8e 00 00 4c 76 00 00 40 7a 00 00 40 75];
	};

	qcom,pc-temp-y5-lut {
		qcom,lut-col-legend = <0xfffffff6 0 10 25 40 50>;
		qcom,lut-row-legend = <10000 9800 9600 9400 9200 9000 8800 8600
		                       8400 8200 8000 7800 7600 7400 7200 7000
		                       6800 6600 6400 6200 6000 5800 5600 5400
		                       5200 5000 4800 4600 4400 4200 4000 3800
		                       3600 3400 3200 3000 2800 2600 2400 2200
		                       2000 1800 1600 1400 1200 1000 900 800
		                       700 600 500 400 300 200 100 0>;
		qcom,lut-data = [00 00 36 f1 00 00 45 1c 00 00 51 bb 00 00 50 dc 00 00 55 f5 00 00 5a 68 00 00 3a 78 00 00 46 7d 00 00 52 50 00 00 53 14 00 00 52 4f 00 00 55 e2 00 00 3e 5b 00 00 49 25 00 00 52 6f 00 00 54 08 00 00 4c d8 00 00 50 4a 00 00 42 17 00 00 4c 21 00 00 52 31 00 00 53 ed 00 00 47 17 00 00 4a ef 00 00 45 2c 00 00 4e 7b 00 00 51 b2 00 00 52 fc 00 00 42 94 00 00 47 1e 00 00 47 1b 00 00 4f 45 00 00 51 0a 00 00 50 fc 00 00 40 bc 00 00 46 1c 00 00 48 56 00 00 4f 36 00 00 50 37 00 00 47 6c 00 00 40 20 00 00 47 28 00 00 49 11 00 00 4f 11 00 00 4e fe 00 00 3f 3e 00 00 3f dc 00 00 48 25 00 00 48 e1 00 00 4d f8 00 00 4c 4c 00 00 3f 98 00 00 43 93 00 00 47 6b 00 00 48 11 00 00 4a d2 00 00 47 8e 00 00 40 b3 00 00 4b 01 00 00 45 6d 00 00 47 bb 00 00 47 f6 00 00 44 2e 00 00 40 a0 00 00 4c 35 00 00 43 79 00 00 48 17 00 00 45 45 00 00 42 1f 00 00 3e a1 00 00 49 4e 00 00 41 35 00 00 48 d8 00 00 43 74 00 00 40 81 00 00 3c 70 00 00 45 e6 00 00 40 29 00 00 4b 08 00 00 42 f2 00 00 3f 29 00 00 3a 40 00 00 42 03 00 00 44 12 00 00 4f 6e 00 00 42 a9 00 00 3e 09 00 00 38 9e 00 00 3e f8 00 00 49 10 00 00 52 ad 00 00 43 46 00 00 3c f9 00 00 38 79 00 00 3f 86 00 00 48 7a 00 00 55 25 00 00 48 32 00 00 3b d5 00 00 38 74 00 00 41 c0 00 00 44 97 00 00 56 84 00 00 4e 2e 00 00 3b 4a 00 00 38 79 00 00 42 36 00 00 40 bb 00 00 56 96 00 00 54 46 00 00 3e f1 00 00 38 d0 00 00 3f 20 00 00 3c 7a 00 00 56 9e 00 00 59 ce 00 00 46 63 00 00 39 87 00 00 3c b2 00 00 39 ed 00 00 56 90 00 00 5b e7 00 00 4e 77 00 00 40 ef 00 00 3e b9 00 00 3e 75 00 00 55 fb 00 00 5d 07 00 00 58 90 00 00 4d 74 00 00 43 25 00 00 46 eb 00 00 54 d7 00 00 5d 47 00 00 5c 94 00 00 53 5f 00 00 47 2e 00 00 49 55 00 00 4a e9 00 00 59 a1 00 00 59 8e 00 00 56 fd 00 00 4b 7f 00 00 49 fc 00 00 3b 91 00 00 55 1b 00 00 56 26 00 00 57 c8 00 00 4d 23 00 00 4a 29 00 00 36 e5 00 00 53 ce 00 00 56 51 00 00 4e fa 00 00 4c e0 00 00 49 20 00 00 35 84 00 00 53 25 00 00 57 87 00 00 46 1d 00 00 4c 4c 00 00 47 f1 00 00 34 7d 00 00 52 d1 00 00 57 c7 00 00 47 40 00 00 4a 2e 00 00 48 34 00 00 33 53 00 00 52 b2 00 00 55 6a 00 00 4a d3 00 00 46 05 00 00 49 22 00 00 32 7f 00 00 52 87 00 00 53 57 00 00 4c 75 00 00 43 d4 00 00 48 d9 00 00 32 ab 00 00 4c 5c 00 00 55 2c 00 00 4c ff 00 00 42 b1 00 00 43 23 00 00 33 b9 00 00 40 8b 00 00 58 f4 00 00 4d 92 00 00 42 3c 00 00 3e ce 00 00 34 99 00 00 3e 5d 00 00 5a 01 00 00 4e 7c 00 00 44 55 00 00 40 be 00 00 35 18 00 00 42 94 00 00 5a 1e 00 00 4f 97 00 00 48 31 00 00 44 e1 00 00 35 81 00 00 47 97 00 00 5a 27 00 00 50 ff 00 00 4b 3f 00 00 48 c6 00 00 35 e2 00 00 4c d7 00 00 58 c6 00 00 52 b2 00 00 4e 20 00 00 4d 0d 00 00 36 3b 00 00 51 43 00 00 56 97 00 00 53 3a 00 00 4e ea 00 00 4e a2 00 00 36 8d 00 00 4e f2 00 00 55 e3 00 00 52 ee 00 00 4c 8c 00 00 4d fd 00 00 36 e1 00 00 43 63 00 00 55 aa 00 00 52 49 00 00 49 53 00 00 4d 55 00 00 37 24 00 00 3c 2d 00 00 55 36 00 00 4c 95 00 00 46 79 00 00 4d ad 00 00 37 51 00 00 3a 16 00 00 53 02 00 00 46 53 00 00 44 9e 00 00 4e 43 00 00 37 6a 00 00 39 81 00 00 4f c0 00 00 47 19 00 00 46 7e 00 00 46 57 00 00 35 06 00 00 39 e7 00 00 4b 70 00 00 46 27 00 00 46 2b 00 00 42 11 00 00 33 ca 00 00 35 f3 00 00 3c 02 00 00 45 16 00 00 48 ba 00 00 47 f2 00 00 32 bf 00 00 35 5a 00 00 38 78 00 00 44 4c 00 00 45 2f 00 00 4e d5 00 00 ff ff 00 00 34 e6 00 00 39 ae 00 00 49 e5 00 00 4b 1f 00 00 42 63 00 00 38 ba 00 00 38 01 00 00 37 ed 00 00 48 8e 00 00 43 e2 00 00 44 0b 00 00 25 02 00 00 ff ff 00 00 36 f3 00 00 47 15 00 00 43 b0 00 00 52 8b 00 00 26 d7 00 00 e9 bb 00 00 35 9d 00 00 49 0f 00 00 51 9c 00 00 51 83 00 00 27 02 00 00 2e a5 00 00 43 d2 00 00 4c 91 00 00 58 c5 00 00 50 8d 00 00 24 1a 00 00 27 16 00 00 27 9f 00 00 4a 88 00 00 54 ea 00 00 53 e3 00 00 26 54 00 00 24 63 00 00 36 4b 00 00 44 89 00 00 54 8c 00 00 63 23 00 00 5b 57 00 00 23 94 00 00 2b 13 00 00 34 c1 00 00 62 8a 00 00 6b 13 00 00 49 ee 00 00 22 f1 00 00 25 3f 00 00 2a 80 00 00 62 9c 00 00 67 98 00 00 49 ee 00 00 22 f1 00 00 25 3f 00 00 2a 80 00 00 62 9c 00 00 67 98 00 00 49 ee 00 00 22 f1 00 00 25 3f 00 00 2a 80 00 00 62 9c 00 00 67 98];
	};

	qcom,pc-temp-y6-lut {
		qcom,lut-col-legend = <0xfffffff6 0 10 25 40 50>;
		qcom,lut-row-legend = <10000 9800 9600 9400 9200 9000 8800 8600
		                       8400 8200 8000 7800 7600 7400 7200 7000
		                       6800 6600 6400 6200 6000 5800 5600 5400
		                       5200 5000 4800 4600 4400 4200 4000 3800
		                       3600 3400 3200 3000 2800 2600 2400 2200
		                       2000 1800 1600 1400 1200 1000 900 800
		                       700 600 500 400 300 200 100 0>;
		qcom,lut-data = [00 00 15 a4 00 00 14 5b 00 00 13 dd 00 00 13 7a 00 00 13 58 00 00 13 51 00 00 15 ab 00 00 14 66 00 00 13 de 00 00 13 79 00 00 13 57 00 00 13 50 00 00 15 b0 00 00 14 6d 00 00 13 df 00 00 13 77 00 00 13 56 00 00 13 4f 00 00 15 b2 00 00 14 71 00 00 13 df 00 00 13 76 00 00 13 55 00 00 13 4e 00 00 15 b3 00 00 14 72 00 00 13 de 00 00 13 75 00 00 13 54 00 00 13 4e 00 00 15 b3 00 00 14 72 00 00 13 dd 00 00 13 75 00 00 13 54 00 00 13 4e 00 00 15 b0 00 00 14 6f 00 00 13 db 00 00 13 74 00 00 13 54 00 00 13 4e 00 00 15 a9 00 00 14 69 00 00 13 d7 00 00 13 74 00 00 13 55 00 00 13 4f 00 00 15 a3 00 00 14 64 00 00 13 d4 00 00 13 74 00 00 13 55 00 00 13 4f 00 00 15 9c 00 00 14 60 00 00 13 d0 00 00 13 74 00 00 13 55 00 00 13 50 00 00 15 98 00 00 14 5d 00 00 13 ce 00 00 13 75 00 00 13 56 00 00 13 50 00 00 15 96 00 00 14 59 00 00 13 cc 00 00 13 75 00 00 13 57 00 00 13 51 00 00 15 95 00 00 14 56 00 00 13 cb 00 00 13 77 00 00 13 58 00 00 13 52 00 00 15 96 00 00 14 56 00 00 13 cc 00 00 13 78 00 00 13 59 00 00 13 53 00 00 15 99 00 00 14 58 00 00 13 cd 00 00 13 79 00 00 13 5b 00 00 13 54 00 00 15 9b 00 00 14 5b 00 00 13 d0 00 00 13 7c 00 00 13 5c 00 00 13 55 00 00 15 99 00 00 14 64 00 00 13 d3 00 00 13 7f 00 00 13 5e 00 00 13 56 00 00 15 96 00 00 14 6d 00 00 13 d8 00 00 13 83 00 00 13 61 00 00 13 58 00 00 15 8e 00 00 14 6e 00 00 13 e1 00 00 13 89 00 00 13 63 00 00 13 5a 00 00 15 7b 00 00 14 6e 00 00 13 eb 00 00 13 8f 00 00 13 66 00 00 13 5d 00 00 15 6b 00 00 14 6d 00 00 13 ea 00 00 13 93 00 00 13 6a 00 00 13 60 00 00 15 5f 00 00 14 59 00 00 13 de 00 00 13 96 00 00 13 71 00 00 13 66 00 00 15 54 00 00 14 3f 00 00 13 d1 00 00 13 96 00 00 13 74 00 00 13 68 00 00 15 4a 00 00 14 35 00 00 13 c2 00 00 13 86 00 00 13 68 00 00 13 5f 00 00 15 40 00 00 14 2e 00 00 13 b7 00 00 13 74 00 00 13 5a 00 00 13 54 00 00 15 3c 00 00 14 2c 00 00 13 b4 00 00 13 72 00 00 13 58 00 00 13 52 00 00 15 3f 00 00 14 2b 00 00 13 b3 00 00 13 71 00 00 13 57 00 00 13 52 00 00 15 43 00 00 14 2b 00 00 13 b3 00 00 13 71 00 00 13 57 00 00 13 52 00 00 15 4a 00 00 14 2b 00 00 13 b4 00 00 13 72 00 00 13 58 00 00 13 53 00 00 15 57 00 00 14 2c 00 00 13 b6 00 00 13 73 00 00 13 59 00 00 13 54 00 00 15 66 00 00 14 2d 00 00 13 b7 00 00 13 75 00 00 13 5a 00 00 13 55 00 00 15 78 00 00 14 2e 00 00 13 b9 00 00 13 78 00 00 13 5c 00 00 13 56 00 00 15 8c 00 00 14 30 00 00 13 bb 00 00 13 7b 00 00 13 5e 00 00 13 57 00 00 15 a1 00 00 14 35 00 00 13 bc 00 00 13 7d 00 00 13 61 00 00 13 5a 00 00 15 b8 00 00 14 42 00 00 13 be 00 00 13 7e 00 00 13 62 00 00 13 5b 00 00 15 d2 00 00 14 4f 00 00 13 c0 00 00 13 7e 00 00 13 61 00 00 13 59 00 00 15 f1 00 00 14 5d 00 00 13 c3 00 00 13 7e 00 00 13 5e 00 00 13 56 00 00 16 13 00 00 14 6e 00 00 13 c7 00 00 13 7c 00 00 13 5c 00 00 13 54 00 00 16 3b 00 00 14 80 00 00 13 cb 00 00 13 77 00 00 13 59 00 00 13 53 00 00 16 67 00 00 14 93 00 00 13 cf 00 00 13 75 00 00 13 58 00 00 13 53 00 00 16 97 00 00 14 a7 00 00 13 d5 00 00 13 76 00 00 13 59 00 00 13 54 00 00 16 cb 00 00 14 bb 00 00 13 dd 00 00 13 77 00 00 13 5a 00 00 13 55 00 00 17 0a 00 00 14 d5 00 00 13 e9 00 00 13 78 00 00 13 59 00 00 13 54 00 00 17 5c 00 00 14 f9 00 00 13 f4 00 00 13 78 00 00 13 59 00 00 13 53 00 00 17 d1 00 00 15 2b 00 00 13 f5 00 00 13 75 00 00 13 56 00 00 13 51 00 00 18 67 00 00 15 62 00 00 14 13 00 00 13 7c 00 00 13 5a 00 00 13 54 00 00 18 e4 00 00 15 9d 00 00 14 2b 00 00 13 80 00 00 13 5c 00 00 13 56 00 00 19 75 00 00 15 ea 00 00 14 4f 00 00 13 88 00 00 13 61 00 00 13 5c 00 00 1a 44 00 00 16 56 00 00 14 88 00 00 13 91 00 00 13 6e 00 00 13 69 00 00 1b f5 00 00 16 ff 00 00 14 ce 00 00 13 90 00 00 13 65 00 00 13 60 00 00 21 ad 00 00 18 23 00 00 15 45 00 00 13 8d 00 00 13 5f 00 00 13 5a 00 00 2d cd 00 00 19 70 00 00 16 a5 00 00 13 97 00 00 13 63 00 00 13 5d 00 00 56 94 00 00 1e d0 00 00 19 0a 00 00 13 a9 00 00 13 67 00 00 13 61 00 00 5b 44 00 00 32 67 00 00 25 07 00 00 13 da 00 00 13 79 00 00 13 75 00 00 5b 44 00 00 32 67 00 00 25 07 00 00 13 da 00 00 13 79 00 00 13 75 00 00 5b 44 00 00 32 67 00 00 25 07 00 00 13 da 00 00 13 79 00 00 13 75];
	};
};
